AUTOSAR XML (schema 4-2-2)
package /System
  system System
package /EcuInstance
  18 x ecu instance:
    CVM9: associated-com-i-pdu-group=ipdugroupCVM9OUT
      can communication controller CVM9_CanCluster: can-controller-attributes=can-controller-configuration={sync-jump-width=0, time-seg-1=0, time-seg-2=0}
      can communication connector connectorCVM9_CanCluster: comm-controller=CVM9_CanCluster
    CVM10: associated-com-i-pdu-group=ipdugroupCVM10OUT
      can communication controller CVM10_CanCluster: can-controller-attributes=can-controller-configuration={sync-jump-width=0, time-seg-1=0, time-seg-2=0}
      can communication connector connectorCVM10_CanCluster: comm-controller=CVM10_CanCluster
    CVM8: associated-com-i-pdu-group=ipdugroupCVM8OUT
      can communication controller CVM8_CanCluster: can-controller-attributes=can-controller-configuration={sync-jump-width=0, time-seg-1=0, time-seg-2=0}
      can communication connector connectorCVM8_CanCluster: comm-controller=CVM8_CanCluster
    CVM11: associated-com-i-pdu-group=ipdugroupCVM11OUT
      can communication controller CVM11_CanCluster: can-controller-attributes=can-controller-configuration={sync-jump-width=0, time-seg-1=0, time-seg-2=0}
      can communication connector connectorCVM11_CanCluster: comm-controller=CVM11_CanCluster
    CVM7: associated-com-i-pdu-group=ipdugroupCVM7OUT
      can communication controller CVM7_CanCluster: can-controller-attributes=can-controller-configuration={sync-jump-width=0, time-seg-1=0, time-seg-2=0}
      can communication connector connectorCVM7_CanCluster: comm-controller=CVM7_CanCluster
    CVM12: associated-com-i-pdu-group=ipdugroupCVM12OUT
      can communication controller CVM12_CanCluster: can-controller-attributes=can-controller-configuration={sync-jump-width=0, time-seg-1=0, time-seg-2=0}
      can communication connector connectorCVM12_CanCluster: comm-controller=CVM12_CanCluster
    CVM6: associated-com-i-pdu-group=ipdugroupCVM6OUT
      can communication controller CVM6_CanCluster: can-controller-attributes=can-controller-configuration={sync-jump-width=0, time-seg-1=0, time-seg-2=0}
      can communication connector connectorCVM6_CanCluster: comm-controller=CVM6_CanCluster
    CVM5: associated-com-i-pdu-group=ipdugroupCVM5OUT
      can communication controller CVM5_CanCluster: can-controller-attributes=can-controller-configuration={sync-jump-width=0, time-seg-1=0, time-seg-2=0}
      can communication connector connectorCVM5_CanCluster: comm-controller=CVM5_CanCluster
    CVM4: associated-com-i-pdu-group=ipdugroupCVM4OUT
      can communication controller CVM4_CanCluster: can-controller-attributes=can-controller-configuration={sync-jump-width=0, time-seg-1=0, time-seg-2=0}
      can communication connector connectorCVM4_CanCluster: comm-controller=CVM4_CanCluster
    CVM3: associated-com-i-pdu-group=ipdugroupCVM3OUT
      can communication controller CVM3_CanCluster: can-controller-attributes=can-controller-configuration={sync-jump-width=0, time-seg-1=0, time-seg-2=0}
      can communication connector connectorCVM3_CanCluster: comm-controller=CVM3_CanCluster
    DCF: associated-com-i-pdu-group=[ipdugroupDCFOUT, ipdugroupDCFIN]
      can communication controller DCF_CanCluster: can-controller-attributes=can-controller-configuration={sync-jump-width=0, time-seg-1=0, time-seg-2=0}
      can communication connector connectorDCF_CanCluster: comm-controller=DCF_CanCluster
    CMP: associated-com-i-pdu-group=[ipdugroupCMPIN, ipdugroupCMPOUT]
      can communication controller CMP_CanCluster: can-controller-attributes=can-controller-configuration={sync-jump-width=0, time-seg-1=0, time-seg-2=0}
      can communication connector connectorCMP_CanCluster: comm-controller=CMP_CanCluster
    CVM2: associated-com-i-pdu-group=ipdugroupCVM2OUT
      can communication controller CVM2_CanCluster: can-controller-attributes=can-controller-configuration={sync-jump-width=0, time-seg-1=0, time-seg-2=0}
      can communication connector connectorCVM2_CanCluster: comm-controller=CVM2_CanCluster
    CVM1: associated-com-i-pdu-group=ipdugroupCVM1OUT
      can communication controller CVM1_CanCluster: can-controller-attributes=can-controller-configuration={sync-jump-width=0, time-seg-1=0, time-seg-2=0}
      can communication connector connectorCVM1_CanCluster: comm-controller=CVM1_CanCluster
    DCU: associated-com-i-pdu-group=[ipdugroupDCUIN, ipdugroupDCUOUT]
      can communication controller DCU_CanCluster: can-controller-attributes=can-controller-configuration={sync-jump-width=0, time-seg-1=0, time-seg-2=0}
      can communication connector connectorDCU_CanCluster: comm-controller=DCU_CanCluster
    HRB: associated-com-i-pdu-group=[ipdugroupHRBIN, ipdugroupHRBOUT]
      can communication controller HRB_CanCluster: can-controller-attributes=can-controller-configuration={sync-jump-width=0, time-seg-1=0, time-seg-2=0}
      can communication connector connectorHRB_CanCluster: comm-controller=HRB_CanCluster
    FCU: associated-com-i-pdu-group=[ipdugroupFCUIN, ipdugroupFCUOUT]
      can communication controller FCU_CanCluster: can-controller-attributes=can-controller-configuration={sync-jump-width=0, time-seg-1=0, time-seg-2=0}
      can communication connector connectorFCU_CanCluster: comm-controller=FCU_CanCluster
    HCU: associated-com-i-pdu-group=[ipdugroupHCUOUT, ipdugroupHCUIN]
      can communication controller HCU_CanCluster: can-controller-attributes=can-controller-configuration={sync-jump-width=0, time-seg-1=0, time-seg-2=0}
      can communication connector connectorHCU_CanCluster: comm-controller=HCU_CanCluster
package /VehicleTopology
  can cluster CanCluster: protocol-name=CAN, protocol-version=CAN, speed=1000
    can physical channel CanCluster
      comm-connectors:
        connectorCVM9_CanCluster
        connectorCVM10_CanCluster
        connectorCVM8_CanCluster
        connectorCVM11_CanCluster
        connectorCVM7_CanCluster
        connectorCVM12_CanCluster
        connectorCVM6_CanCluster
        connectorCVM5_CanCluster
        connectorCVM4_CanCluster
        connectorCVM3_CanCluster
        connectorDCF_CanCluster
        connectorCMP_CanCluster
        connectorCVM2_CanCluster
        connectorCVM1_CanCluster
        connectorDCU_CanCluster
        connectorHRB_CanCluster
        connectorFCU_CanCluster
        connectorHCU_CanCluster
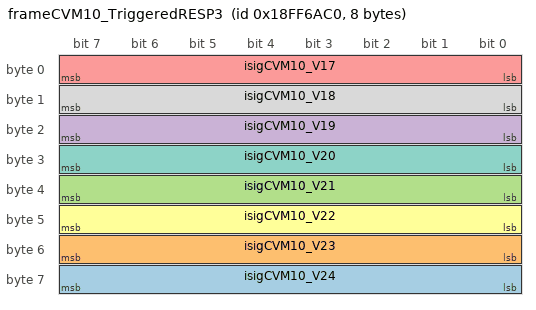
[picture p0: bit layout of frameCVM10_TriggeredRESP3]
      frame frameCVM10_TriggeredRESP3: id 0x18FF6AC0, from CVM10, to FCU, frame-length=8, can-addressing-mode=EXTENDED
        pdu ipduCVM10_TriggeredRESP3: length=8
          signal isigCVM10_V24: start 56, 8 bit, little-endian, system signal syssigCVM10_V24, init-value=0, base-type=uint8, compu-method=CVM10_V24, transfer-property=PENDING, to FCU
          signal isigCVM10_V23: start 48, 8 bit, little-endian, system signal syssigCVM10_V23, init-value=0, base-type=uint8, compu-method=CVM10_V23, transfer-property=PENDING, to FCU
          signal isigCVM10_V21: start 32, 8 bit, little-endian, system signal syssigCVM10_V21, init-value=0, base-type=uint8, compu-method=CVM10_V21, transfer-property=PENDING, to FCU
          signal isigCVM10_V19: start 16, 8 bit, little-endian, system signal syssigCVM10_V19, init-value=0, base-type=uint8, compu-method=CVM10_V19, transfer-property=PENDING, to FCU
          signal isigCVM10_V17: start 0, 8 bit, little-endian, system signal syssigCVM10_V17, init-value=0, base-type=uint8, compu-method=CVM10_V17, transfer-property=PENDING, to FCU
          signal isigCVM10_V22: start 40, 8 bit, little-endian, system signal syssigCVM10_V22, init-value=0, base-type=uint8, compu-method=CVM10_V22, transfer-property=PENDING, to FCU
          signal isigCVM10_V20: start 24, 8 bit, little-endian, system signal syssigCVM10_V20, init-value=0, base-type=uint8, compu-method=CVM10_V20, transfer-property=PENDING, to FCU
          signal isigCVM10_V18: start 8, 8 bit, little-endian, system signal syssigCVM10_V18, init-value=0, base-type=uint8, compu-method=CVM10_V18, transfer-property=PENDING, to FCU
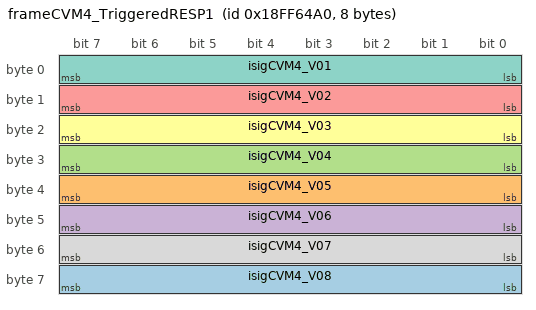
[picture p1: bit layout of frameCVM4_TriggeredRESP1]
      frame frameCVM4_TriggeredRESP1: id 0x18FF64A0, from CVM4, to FCU, frame-length=8, can-addressing-mode=EXTENDED
        pdu ipduCVM4_TriggeredRESP1: length=8
          signal isigCVM4_V08: start 56, 8 bit, little-endian, system signal syssigCVM4_V08, init-value=0, base-type=uint8, compu-method=CVM4_V08, transfer-property=PENDING, to FCU
          signal isigCVM4_V05: start 32, 8 bit, little-endian, system signal syssigCVM4_V05, init-value=0, base-type=uint8, compu-method=CVM4_V05, transfer-property=PENDING, to FCU
          signal isigCVM4_V04: start 24, 8 bit, little-endian, system signal syssigCVM4_V04, init-value=0, base-type=uint8, compu-method=CVM4_V04, transfer-property=PENDING, to FCU
          signal isigCVM4_V06: start 40, 8 bit, little-endian, system signal syssigCVM4_V06, init-value=0, base-type=uint8, compu-method=CVM4_V06, transfer-property=PENDING, to FCU
          signal isigCVM4_V02: start 8, 8 bit, little-endian, system signal syssigCVM4_V02, init-value=0, base-type=uint8, compu-method=CVM4_V02, transfer-property=PENDING, to FCU
          signal isigCVM4_V03: start 16, 8 bit, little-endian, system signal syssigCVM4_V03, init-value=0, base-type=uint8, compu-method=CVM4_V03, transfer-property=PENDING, to FCU
          signal isigCVM4_V01: start 0, 8 bit, little-endian, system signal syssigCVM4_V01, init-value=0, base-type=uint8, compu-method=CVM4_V01, transfer-property=PENDING, to FCU
          signal isigCVM4_V07: start 48, 8 bit, little-endian, system signal syssigCVM4_V07, init-value=0, base-type=uint8, compu-method=CVM4_V07, transfer-property=PENDING, to FCU
      frame frameCANC_HRB_CMD_Manual: id 0xCFFA63D, from FCU, to HRB, frame-length=8, can-addressing-mode=EXTENDED
        pdu ipduCANC_HRB_CMD_Manual: length=8, minimum-delay=0.0, transmission-mode-true-timing=cyclic-timing={time-offset=0.0, time-period=0.1}
          signal isigQ_HRBSet_Manual: start 0, 16 bit, little-endian, system signal syssigQ_HRBSet_Manual, init-value=0, base-type=uint16, compu-method=Q_HRBSet_Manual, transfer-property=PENDING, to HRB
          signal isigHRB_MFGEn_Manual: start 34, 2 bit, little-endian, system signal syssigHRB_MFGEn_Manual, init-value=0, base-type=uint8, compu-method=HRB_MFGEn_Manual, transfer-property=PENDING, to HRB
          signal isigHRB_PumpEn_Manual: start 32, 2 bit, little-endian, system signal syssigHRB_PumpEn_Manual, init-value=0, base-type=uint8, compu-method=HRB_PumpEn_Manual, transfer-property=PENDING, to HRB
          signal isigSpd_HRBSet_Manual: start 16, 16 bit, little-endian, system signal syssigSpd_HRBSet_Manual, init-value=0, base-type=uint16, compu-method=Spd_HRBSet_Manual, transfer-property=PENDING, to HRB
      frame frameCVM12_RESP: id 0x18FF6C10, from CVM12, to FCU, frame-length=8, can-addressing-mode=EXTENDED
        pdu ipduCVM12_RESP: length=8, minimum-delay=0.0, transmission-mode-true-timing=cyclic-timing={time-offset=0.0, time-period=0.1}
          signal isigCVM12_VMin: start 16, 8 bit, little-endian, system signal syssigCVM12_VMin, init-value=0, base-type=uint8, compu-method=CVM12_VMin, transfer-property=PENDING, to FCU
          signal isigCVM12_Var: start 48, 16 bit, little-endian, system signal syssigCVM12_Var, init-value=0, base-type=uint16, compu-method=CVM12_Var, transfer-property=PENDING, to FCU
          signal isigCVM12_Total: start 32, 16 bit, little-endian, system signal syssigCVM12_Total, init-value=0, base-type=uint16, compu-method=CVM12_Total, transfer-property=PENDING, to FCU
          signal isigCVM12_VMinCH: start 24, 8 bit, little-endian, system signal syssigCVM12_VMinCH, init-value=0, base-type=uint8, compu-method=CVM12_VMinCH, transfer-property=PENDING, to FCU
          signal isigCVM12_VMaxCH: start 8, 8 bit, little-endian, system signal syssigCVM12_VMaxCH, init-value=0, base-type=uint8, compu-method=CVM12_VMaxCH, transfer-property=PENDING, to FCU
          signal isigCVM12_VMax: start 0, 8 bit, little-endian, system signal syssigCVM12_VMax, init-value=0, base-type=uint8, compu-method=CVM12_VMax, transfer-property=PENDING, to FCU
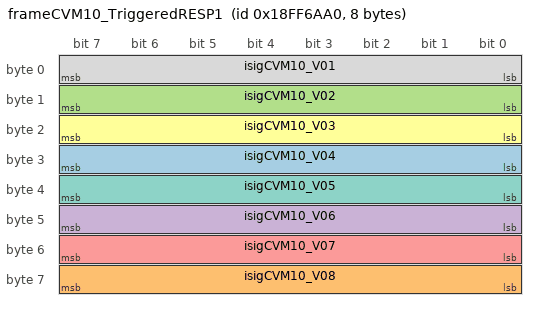
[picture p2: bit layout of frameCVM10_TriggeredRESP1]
      frame frameCVM10_TriggeredRESP1: id 0x18FF6AA0, from CVM10, to FCU, frame-length=8, can-addressing-mode=EXTENDED
        pdu ipduCVM10_TriggeredRESP1: length=8
          signal isigCVM10_V04: start 24, 8 bit, little-endian, system signal syssigCVM10_V04, init-value=0, base-type=uint8, compu-method=CVM10_V04, transfer-property=PENDING, to FCU
          signal isigCVM10_V08: start 56, 8 bit, little-endian, system signal syssigCVM10_V08, init-value=0, base-type=uint8, compu-method=CVM10_V08, transfer-property=PENDING, to FCU
          signal isigCVM10_V02: start 8, 8 bit, little-endian, system signal syssigCVM10_V02, init-value=0, base-type=uint8, compu-method=CVM10_V02, transfer-property=PENDING, to FCU
          signal isigCVM10_V06: start 40, 8 bit, little-endian, system signal syssigCVM10_V06, init-value=0, base-type=uint8, compu-method=CVM10_V06, transfer-property=PENDING, to FCU
          signal isigCVM10_V07: start 48, 8 bit, little-endian, system signal syssigCVM10_V07, init-value=0, base-type=uint8, compu-method=CVM10_V07, transfer-property=PENDING, to FCU
          signal isigCVM10_V03: start 16, 8 bit, little-endian, system signal syssigCVM10_V03, init-value=0, base-type=uint8, compu-method=CVM10_V03, transfer-property=PENDING, to FCU
          signal isigCVM10_V05: start 32, 8 bit, little-endian, system signal syssigCVM10_V05, init-value=0, base-type=uint8, compu-method=CVM10_V05, transfer-property=PENDING, to FCU
          signal isigCVM10_V01: start 0, 8 bit, little-endian, system signal syssigCVM10_V01, init-value=0, base-type=uint8, compu-method=CVM10_V01, transfer-property=PENDING, to FCU
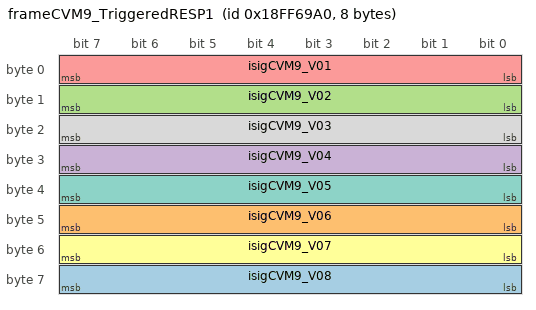
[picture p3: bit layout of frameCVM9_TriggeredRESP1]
      frame frameCVM9_TriggeredRESP1: id 0x18FF69A0, from CVM9, to FCU, frame-length=8, can-addressing-mode=EXTENDED
        pdu ipduCVM9_TriggeredRESP1: length=8
          signal isigCVM9_V08: start 56, 8 bit, little-endian, system signal syssigCVM9_V08, init-value=0, base-type=uint8, compu-method=CVM9_V08, transfer-property=PENDING, to FCU
          signal isigCVM9_V06: start 40, 8 bit, little-endian, system signal syssigCVM9_V06, init-value=0, base-type=uint8, compu-method=CVM9_V06, transfer-property=PENDING, to FCU
          signal isigCVM9_V02: start 8, 8 bit, little-endian, system signal syssigCVM9_V02, init-value=0, base-type=uint8, compu-method=CVM9_V02, transfer-property=PENDING, to FCU
          signal isigCVM9_V04: start 24, 8 bit, little-endian, system signal syssigCVM9_V04, init-value=0, base-type=uint8, compu-method=CVM9_V04, transfer-property=PENDING, to FCU
          signal isigCVM9_V01: start 0, 8 bit, little-endian, system signal syssigCVM9_V01, init-value=0, base-type=uint8, compu-method=CVM9_V01, transfer-property=PENDING, to FCU
          signal isigCVM9_V07: start 48, 8 bit, little-endian, system signal syssigCVM9_V07, init-value=0, base-type=uint8, compu-method=CVM9_V07, transfer-property=PENDING, to FCU
          signal isigCVM9_V05: start 32, 8 bit, little-endian, system signal syssigCVM9_V05, init-value=0, base-type=uint8, compu-method=CVM9_V05, transfer-property=PENDING, to FCU
          signal isigCVM9_V03: start 16, 8 bit, little-endian, system signal syssigCVM9_V03, init-value=0, base-type=uint8, compu-method=CVM9_V03, transfer-property=PENDING, to FCU
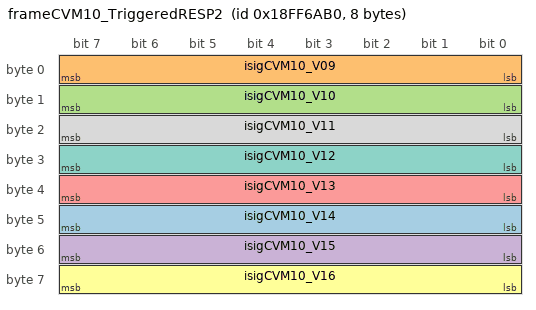
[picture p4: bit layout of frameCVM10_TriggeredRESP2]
      frame frameCVM10_TriggeredRESP2: id 0x18FF6AB0, from CVM10, to FCU, frame-length=8, can-addressing-mode=EXTENDED
        pdu ipduCVM10_TriggeredRESP2: length=8
          signal isigCVM10_V14: start 40, 8 bit, little-endian, system signal syssigCVM10_V14, init-value=0, base-type=uint8, compu-method=CVM10_V14, transfer-property=PENDING, to FCU
          signal isigCVM10_V09: start 0, 8 bit, little-endian, system signal syssigCVM10_V09, init-value=0, base-type=uint8, compu-method=CVM10_V09, transfer-property=PENDING, to FCU
          signal isigCVM10_V10: start 8, 8 bit, little-endian, system signal syssigCVM10_V10, init-value=0, base-type=uint8, compu-method=CVM10_V10, transfer-property=PENDING, to FCU
          signal isigCVM10_V15: start 48, 8 bit, little-endian, system signal syssigCVM10_V15, init-value=0, base-type=uint8, compu-method=CVM10_V15, transfer-property=PENDING, to FCU
          signal isigCVM10_V13: start 32, 8 bit, little-endian, system signal syssigCVM10_V13, init-value=0, base-type=uint8, compu-method=CVM10_V13, transfer-property=PENDING, to FCU
          signal isigCVM10_V16: start 56, 8 bit, little-endian, system signal syssigCVM10_V16, init-value=0, base-type=uint8, compu-method=CVM10_V16, transfer-property=PENDING, to FCU
          signal isigCVM10_V12: start 24, 8 bit, little-endian, system signal syssigCVM10_V12, init-value=0, base-type=uint8, compu-method=CVM10_V12, transfer-property=PENDING, to FCU
          signal isigCVM10_V11: start 16, 8 bit, little-endian, system signal syssigCVM10_V11, init-value=0, base-type=uint8, compu-method=CVM10_V11, transfer-property=PENDING, to FCU
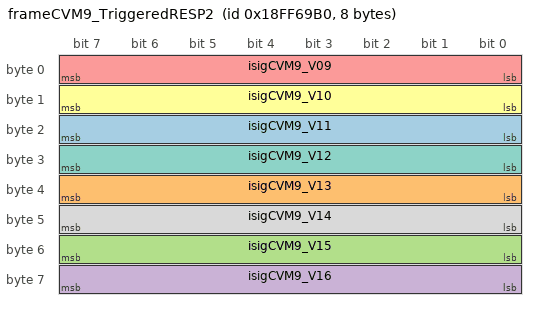
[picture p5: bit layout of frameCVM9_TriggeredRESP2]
      frame frameCVM9_TriggeredRESP2: id 0x18FF69B0, from CVM9, to FCU, frame-length=8, can-addressing-mode=EXTENDED
        pdu ipduCVM9_TriggeredRESP2: length=8
          signal isigCVM9_V11: start 16, 8 bit, little-endian, system signal syssigCVM9_V11, init-value=0, base-type=uint8, compu-method=CVM9_V11, transfer-property=PENDING, to FCU
          signal isigCVM9_V13: start 32, 8 bit, little-endian, system signal syssigCVM9_V13, init-value=0, base-type=uint8, compu-method=CVM9_V13, transfer-property=PENDING, to FCU
          signal isigCVM9_V15: start 48, 8 bit, little-endian, system signal syssigCVM9_V15, init-value=0, base-type=uint8, compu-method=CVM9_V15, transfer-property=PENDING, to FCU
          signal isigCVM9_V16: start 56, 8 bit, little-endian, system signal syssigCVM9_V16, init-value=0, base-type=uint8, compu-method=CVM9_V16, transfer-property=PENDING, to FCU
          signal isigCVM9_V09: start 0, 8 bit, little-endian, system signal syssigCVM9_V09, init-value=0, base-type=uint8, compu-method=CVM9_V09, transfer-property=PENDING, to FCU
          signal isigCVM9_V10: start 8, 8 bit, little-endian, system signal syssigCVM9_V10, init-value=0, base-type=uint8, compu-method=CVM9_V10, transfer-property=PENDING, to FCU
          signal isigCVM9_V12: start 24, 8 bit, little-endian, system signal syssigCVM9_V12, init-value=0, base-type=uint8, compu-method=CVM9_V12, transfer-property=PENDING, to FCU
          signal isigCVM9_V14: start 40, 8 bit, little-endian, system signal syssigCVM9_V14, init-value=0, base-type=uint8, compu-method=CVM9_V14, transfer-property=PENDING, to FCU
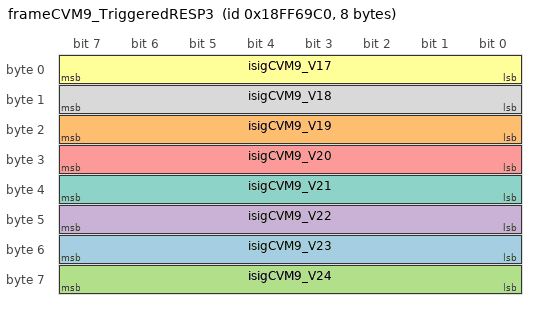
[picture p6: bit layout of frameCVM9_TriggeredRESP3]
      frame frameCVM9_TriggeredRESP3: id 0x18FF69C0, from CVM9, to FCU, frame-length=8, can-addressing-mode=EXTENDED
        pdu ipduCVM9_TriggeredRESP3: length=8
          signal isigCVM9_V23: start 48, 8 bit, little-endian, system signal syssigCVM9_V23, init-value=0, base-type=uint8, compu-method=CVM9_V23, transfer-property=PENDING, to FCU
          signal isigCVM9_V19: start 16, 8 bit, little-endian, system signal syssigCVM9_V19, init-value=0, base-type=uint8, compu-method=CVM9_V19, transfer-property=PENDING, to FCU
          signal isigCVM9_V24: start 56, 8 bit, little-endian, system signal syssigCVM9_V24, init-value=0, base-type=uint8, compu-method=CVM9_V24, transfer-property=PENDING, to FCU
          signal isigCVM9_V22: start 40, 8 bit, little-endian, system signal syssigCVM9_V22, init-value=0, base-type=uint8, compu-method=CVM9_V22, transfer-property=PENDING, to FCU
          signal isigCVM9_V20: start 24, 8 bit, little-endian, system signal syssigCVM9_V20, init-value=0, base-type=uint8, compu-method=CVM9_V20, transfer-property=PENDING, to FCU
          signal isigCVM9_V17: start 0, 8 bit, little-endian, system signal syssigCVM9_V17, init-value=0, base-type=uint8, compu-method=CVM9_V17, transfer-property=PENDING, to FCU
          signal isigCVM9_V21: start 32, 8 bit, little-endian, system signal syssigCVM9_V21, init-value=0, base-type=uint8, compu-method=CVM9_V21, transfer-property=PENDING, to FCU
          signal isigCVM9_V18: start 8, 8 bit, little-endian, system signal syssigCVM9_V18, init-value=0, base-type=uint8, compu-method=CVM9_V18, transfer-property=PENDING, to FCU
      frame frameCANC_CVM_TriggeredCMD_Manual: id 0xFF6002, from FCU, frame-length=8, can-addressing-mode=EXTENDED
        pdu ipduCANC_CVM_TriggeredCMD_Manual: length=8, minimum-delay=0.0, transmission-mode-true-timing=cyclic-timing={time-offset=0.0, time-period=0.1}
          signal isigCVM_Triggered_Manual: start 0, 1 bit, little-endian, system signal syssigCVM_Triggered_Manual, init-value=0, base-type=uint8, compu-method=CVM_Triggered_Manual, transfer-property=PENDING
      frame frameCVM8_RESP: id 0x18FF6810, from CVM8, to FCU, frame-length=8, can-addressing-mode=EXTENDED
        pdu ipduCVM8_RESP: length=8
          signal isigCVM8_Var: start 48, 16 bit, little-endian, system signal syssigCVM8_Var, init-value=0, base-type=uint16, compu-method=CVM8_Var, transfer-property=PENDING, to FCU
          signal isigCVM8_VMaxCH: start 8, 8 bit, little-endian, system signal syssigCVM8_VMaxCH, init-value=0, base-type=uint8, compu-method=CVM8_VMaxCH, transfer-property=PENDING, to FCU
          signal isigCVM8_VMinCH: start 24, 8 bit, little-endian, system signal syssigCVM8_VMinCH, init-value=0, base-type=uint8, compu-method=CVM8_VMinCH, transfer-property=PENDING, to FCU
          signal isigCVM8_VMin: start 16, 8 bit, little-endian, system signal syssigCVM8_VMin, init-value=0, base-type=uint8, compu-method=CVM8_VMin, transfer-property=PENDING, to FCU
          signal isigCVM8_VMax: start 0, 8 bit, little-endian, system signal syssigCVM8_VMax, init-value=0, base-type=uint8, compu-method=CVM8_VMax, transfer-property=PENDING, to FCU
          signal isigCVM8_Total: start 32, 16 bit, little-endian, system signal syssigCVM8_Total, init-value=0, base-type=uint16, compu-method=CVM8_Total, transfer-property=PENDING, to FCU
      frame frameCVM1_RESP: id 0x18FF6110, from CVM1, to FCU, frame-length=8, can-addressing-mode=EXTENDED
        pdu ipduCVM1_RESP: length=8, minimum-delay=0.0, transmission-mode-true-timing=cyclic-timing={time-offset=0.0, time-period=0.1}
          signal isigCVM1_VMax: start 0, 8 bit, little-endian, system signal syssigCVM1_VMax, init-value=0, base-type=uint8, compu-method=CVM1_VMax, transfer-property=PENDING, to FCU
          signal isigCVM1_VMin: start 16, 8 bit, little-endian, system signal syssigCVM1_VMin, init-value=0, base-type=uint8, compu-method=CVM1_VMin, transfer-property=PENDING, to FCU
          signal isigCVM1_VMaxCH: start 8, 8 bit, little-endian, system signal syssigCVM1_VMaxCH, init-value=0, base-type=uint8, compu-method=CVM1_VMaxCH, transfer-property=PENDING, to FCU
          signal isigCVM1_VMinCH: start 24, 8 bit, little-endian, system signal syssigCVM1_VMinCH, init-value=0, base-type=uint8, compu-method=CVM1_VMinCH, transfer-property=PENDING, to FCU
          signal isigCVM1_Total: start 32, 16 bit, little-endian, system signal syssigCVM1_Total, init-value=0, base-type=uint16, compu-method=CVM1_Total, transfer-property=PENDING, to FCU
          signal isigCVM1_Var: start 48, 16 bit, little-endian, system signal syssigCVM1_Var, init-value=0, base-type=uint16, compu-method=CVM1_Var, transfer-property=PENDING, to FCU
      frame frameCVM11_RESP: id 0x18FF6B10, from CVM11, to FCU, frame-length=8, can-addressing-mode=EXTENDED
        pdu ipduCVM11_RESP: length=8, minimum-delay=0.0, transmission-mode-true-timing=cyclic-timing={time-offset=0.0, time-period=0.1}
          signal isigCVM11_Var: start 48, 16 bit, little-endian, system signal syssigCVM11_Var, init-value=0, base-type=uint16, compu-method=CVM11_Var, transfer-property=PENDING, to FCU
          signal isigCVM11_VMin: start 16, 8 bit, little-endian, system signal syssigCVM11_VMin, init-value=0, base-type=uint8, compu-method=CVM11_VMin, transfer-property=PENDING, to FCU
          signal isigCVM11_Total: start 32, 16 bit, little-endian, system signal syssigCVM11_Total, init-value=0, base-type=uint16, compu-method=CVM11_Total, transfer-property=PENDING, to FCU
          signal isigCVM11_VMinCH: start 24, 8 bit, little-endian, system signal syssigCVM11_VMinCH, init-value=0, base-type=uint8, compu-method=CVM11_VMinCH, transfer-property=PENDING, to FCU
          signal isigCVM11_VMax: start 0, 8 bit, little-endian, system signal syssigCVM11_VMax, init-value=0, base-type=uint8, compu-method=CVM11_VMax, transfer-property=PENDING, to FCU
          signal isigCVM11_VMaxCH: start 8, 8 bit, little-endian, system signal syssigCVM11_VMaxCH, init-value=0, base-type=uint8, compu-method=CVM11_VMaxCH, transfer-property=PENDING, to FCU
      frame frameCANC_DCU_CMD1_Manual: id 0xFF1101, from FCU, to DCU, frame-length=8, can-addressing-mode=EXTENDED
        pdu ipduCANC_DCU_CMD1_Manual: length=8, minimum-delay=0.0, transmission-mode-true-timing=cyclic-timing={time-offset=0.0, time-period=0.1}
          signal isigFC_OutputPower_Manual: start 48, 8 bit, little-endian, system signal syssigFC_OutputPower_Manual, init-value=0, base-type=uint8, compu-method=FC_OutputPower_Manual, transfer-property=PENDING
          signal isigDCU_Mode_Manual: start 56, 8 bit, little-endian, system signal syssigDCU_Mode_Manual, init-value=0, base-type=uint8, compu-method=DCU_Mode_Manual, transfer-property=PENDING, to DCU
          signal isigT_FCSet_Manual: start 0, 8 bit, little-endian, system signal syssigT_FCSet_Manual, init-value=0, base-type=uint8, compu-method=T_FCSet_Manual, transfer-property=PENDING, to DCU
          signal isigTDiff_FCSet_Manual: start 16, 8 bit, little-endian, system signal syssigTDiff_FCSet_Manual, init-value=0, base-type=uint8, compu-method=TDiff_FCSet_Manual, transfer-property=PENDING, to DCU
          signal isigT_AMB_Manual: start 40, 8 bit, little-endian, system signal syssigT_AMB_Manual, init-value=0, base-type=uint8, compu-method=T_AMB_Manual, transfer-property=PENDING
      frame frameDCF_RESP1: id 0x18FF3110, from DCF, to FCU, frame-length=8, can-addressing-mode=EXTENDED
        pdu ipduDCF_RESP1: length=8, minimum-delay=0.0, transmission-mode-true-timing=cyclic-timing={time-offset=0.0, time-period=0.1}
          signal isigIIn_DCF: start 48, 16 bit, little-endian, system signal syssigIIn_DCF, init-value=0, base-type=uint16, compu-method=IIn_DCF, transfer-property=PENDING, to FCU
          signal isigIOut_DCF: start 16, 16 bit, little-endian, system signal syssigIOut_DCF, init-value=0, base-type=uint16, compu-method=IOut_DCF, transfer-property=PENDING, to FCU
          signal isigVOut_DCF: start 0, 16 bit, little-endian, system signal syssigVOut_DCF, init-value=0, base-type=uint16, compu-method=VOut_DCF, transfer-property=PENDING, to FCU
          signal isigVIn1_DCF: start 32, 16 bit, little-endian, system signal syssigVIn1_DCF, init-value=0, base-type=uint16, compu-method=VIn1_DCF, transfer-property=PENDING, to FCU
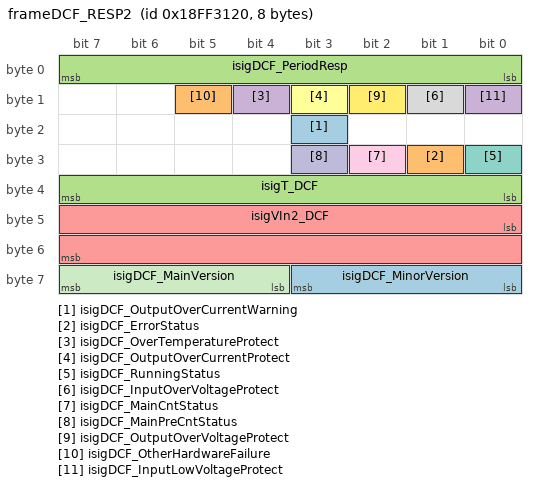
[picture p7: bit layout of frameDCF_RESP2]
      frame frameDCF_RESP2: id 0x18FF3120, from DCF, to FCU, frame-length=8, can-addressing-mode=EXTENDED
        pdu ipduDCF_RESP2: length=8
          signal isigDCF_OutputOverCurrentWarning: start 19, 1 bit, little-endian, system signal syssigDCF_OutputOverCurrentWarning, init-value=0, base-type=uint8, compu-method=DCF_OutputOverCurrentWarning, transfer-property=PENDING, to FCU
          signal isigDCF_ErrorStatus: start 25, 1 bit, little-endian, system signal syssigDCF_ErrorStatus, init-value=0, base-type=uint8, compu-method=DCF_ErrorStatus, transfer-property=PENDING
          signal isigT_DCF: start 32, 8 bit, little-endian, system signal syssigT_DCF, init-value=0, base-type=uint8, compu-method=T_DCF, transfer-property=PENDING, to FCU
          signal isigDCF_OverTemperatureProtect: start 12, 1 bit, little-endian, system signal syssigDCF_OverTemperatureProtect, init-value=0, base-type=uint8, compu-method=DCF_OverTemperatureProtect, transfer-property=PENDING, to FCU
          signal isigVIn2_DCF: start 40, 16 bit, little-endian, system signal syssigVIn2_DCF, init-value=0, base-type=uint16, compu-method=VIn2_DCF, transfer-property=PENDING, to FCU
          signal isigDCF_OutputOverCurrentProtect: start 11, 1 bit, little-endian, system signal syssigDCF_OutputOverCurrentProtect, init-value=0, base-type=uint8, compu-method=DCF_OutputOverCurrentProtect, transfer-property=PENDING, to FCU
          signal isigDCF_RunningStatus: start 24, 1 bit, little-endian, system signal syssigDCF_RunningStatus, init-value=0, base-type=uint8, compu-method=DCF_RunningStatus, transfer-property=PENDING
          signal isigDCF_InputOverVoltageProtect: start 9, 1 bit, little-endian, system signal syssigDCF_InputOverVoltageProtect, init-value=0, base-type=uint8, compu-method=DCF_InputOverVoltageProtect, transfer-property=PENDING, to FCU
          signal isigDCF_MainCntStatus: start 26, 1 bit, little-endian, system signal syssigDCF_MainCntStatus, init-value=0, base-type=uint8, compu-method=DCF_MainCntStatus, transfer-property=PENDING, to FCU
          signal isigDCF_MainPreCntStatus: start 27, 1 bit, little-endian, system signal syssigDCF_MainPreCntStatus, init-value=0, base-type=uint8, compu-method=DCF_MainPreCntStatus, transfer-property=PENDING, to FCU
          signal isigDCF_MainVersion: start 60, 4 bit, little-endian, system signal syssigDCF_MainVersion, init-value=0, base-type=uint8, compu-method=DCF_MainVersion, transfer-property=PENDING, to FCU
          signal isigDCF_OutputOverVoltageProtect: start 10, 1 bit, little-endian, system signal syssigDCF_OutputOverVoltageProtect, init-value=0, base-type=uint8, compu-method=DCF_OutputOverVoltageProtect, transfer-property=PENDING, to FCU
          signal isigDCF_MinorVersion: start 56, 4 bit, little-endian, system signal syssigDCF_MinorVersion, init-value=0, base-type=uint8, compu-method=DCF_MinorVersion, transfer-property=PENDING, to FCU
          signal isigDCF_OtherHardwareFailure: start 13, 1 bit, little-endian, system signal syssigDCF_OtherHardwareFailure, init-value=0, base-type=uint8, compu-method=DCF_OtherHardwareFailure, transfer-property=PENDING, to FCU
          signal isigDCF_PeriodResp: start 0, 8 bit, little-endian, system signal syssigDCF_PeriodResp, init-value=0, base-type=uint8, compu-method=DCF_PeriodResp, transfer-property=PENDING, to FCU
          signal isigDCF_InputLowVoltageProtect: start 8, 1 bit, little-endian, system signal syssigDCF_InputLowVoltageProtect, init-value=0, base-type=uint8, compu-method=DCF_InputLowVoltageProtect, transfer-property=PENDING, to FCU
      frame frameCANC_DCU_CMD2_Manual: id 0xFF1102, from FCU, to DCU, frame-length=8, can-addressing-mode=EXTENDED
        pdu ipduCANC_DCU_CMD2_Manual: length=8, minimum-delay=0.0, transmission-mode-true-timing=cyclic-timing={time-offset=0.0, time-period=0.1}
          signal isigWP_Set_Manual: start 32, 8 bit, little-endian, system signal syssigWP_Set_Manual, init-value=0, base-type=uint8, compu-method=WP_Set_Manual, transfer-property=PENDING, to DCU
          signal isigFAN3_Set_Manual: start 16, 8 bit, little-endian, system signal syssigFAN3_Set_Manual, init-value=0, base-type=uint8, compu-method=FAN3_Set_Manual, transfer-property=PENDING, to DCU
          signal isigFAN1_Set_Manual: start 0, 8 bit, little-endian, system signal syssigFAN1_Set_Manual, init-value=0, base-type=uint8, compu-method=FAN1_Set_Manual, transfer-property=PENDING, to DCU
          signal isigTV_DI_Manual: start 56, 1 bit, little-endian, system signal syssigTV_DI_Manual, init-value=0, base-type=uint8, compu-method=TV_DI_Manual, transfer-property=PENDING, to DCU
          signal isigFAN2_Set_Manual: start 8, 8 bit, little-endian, system signal syssigFAN2_Set_Manual, init-value=0, base-type=uint8, compu-method=FAN2_Set_Manual, transfer-property=PENDING, to DCU
          signal isigFAN4_Set_Manual: start 24, 8 bit, little-endian, system signal syssigFAN4_Set_Manual, init-value=0, base-type=uint8, compu-method=FAN4_Set_Manual, transfer-property=PENDING
      frame frameCVM7_RESP: id 0x18FF6710, from CVM7, to FCU, frame-length=8, can-addressing-mode=EXTENDED
        pdu ipduCVM7_RESP: length=8
          signal isigCVM7_VMax: start 0, 8 bit, little-endian, system signal syssigCVM7_VMax, init-value=0, base-type=uint8, compu-method=CVM7_VMax, transfer-property=PENDING, to FCU
          signal isigCVM7_Total: start 32, 16 bit, little-endian, system signal syssigCVM7_Total, init-value=0, base-type=uint16, compu-method=CVM7_Total, transfer-property=PENDING, to FCU
          signal isigCVM7_VMinCH: start 24, 8 bit, little-endian, system signal syssigCVM7_VMinCH, init-value=0, base-type=uint8, compu-method=CVM7_VMinCH, transfer-property=PENDING, to FCU
          signal isigCVM7_VMin: start 16, 8 bit, little-endian, system signal syssigCVM7_VMin, init-value=0, base-type=uint8, compu-method=CVM7_VMin, transfer-property=PENDING, to FCU
          signal isigCVM7_Var: start 48, 16 bit, little-endian, system signal syssigCVM7_Var, init-value=0, base-type=uint16, compu-method=CVM7_Var, transfer-property=PENDING, to FCU
          signal isigCVM7_VMaxCH: start 8, 8 bit, little-endian, system signal syssigCVM7_VMaxCH, init-value=0, base-type=uint8, compu-method=CVM7_VMaxCH, transfer-property=PENDING, to FCU
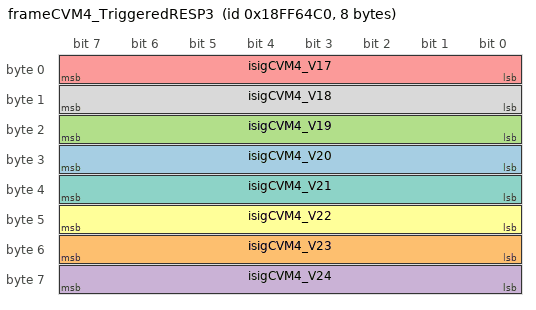
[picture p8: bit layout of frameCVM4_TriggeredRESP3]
      frame frameCVM4_TriggeredRESP3: id 0x18FF64C0, from CVM4, to FCU, frame-length=8, can-addressing-mode=EXTENDED
        pdu ipduCVM4_TriggeredRESP3: length=8
          signal isigCVM4_V20: start 24, 8 bit, little-endian, system signal syssigCVM4_V20, init-value=0, base-type=uint8, compu-method=CVM4_V20, transfer-property=PENDING, to FCU
          signal isigCVM4_V23: start 48, 8 bit, little-endian, system signal syssigCVM4_V23, init-value=0, base-type=uint8, compu-method=CVM4_V23, transfer-property=PENDING, to FCU
          signal isigCVM4_V19: start 16, 8 bit, little-endian, system signal syssigCVM4_V19, init-value=0, base-type=uint8, compu-method=CVM4_V19, transfer-property=PENDING, to FCU
          signal isigCVM4_V24: start 56, 8 bit, little-endian, system signal syssigCVM4_V24, init-value=0, base-type=uint8, compu-method=CVM4_V24, transfer-property=PENDING, to FCU
          signal isigCVM4_V17: start 0, 8 bit, little-endian, system signal syssigCVM4_V17, init-value=0, base-type=uint8, compu-method=CVM4_V17, transfer-property=PENDING, to FCU
          signal isigCVM4_V22: start 40, 8 bit, little-endian, system signal syssigCVM4_V22, init-value=0, base-type=uint8, compu-method=CVM4_V22, transfer-property=PENDING, to FCU
          signal isigCVM4_V21: start 32, 8 bit, little-endian, system signal syssigCVM4_V21, init-value=0, base-type=uint8, compu-method=CVM4_V21, transfer-property=PENDING, to FCU
          signal isigCVM4_V18: start 8, 8 bit, little-endian, system signal syssigCVM4_V18, init-value=0, base-type=uint8, compu-method=CVM4_V18, transfer-property=PENDING, to FCU
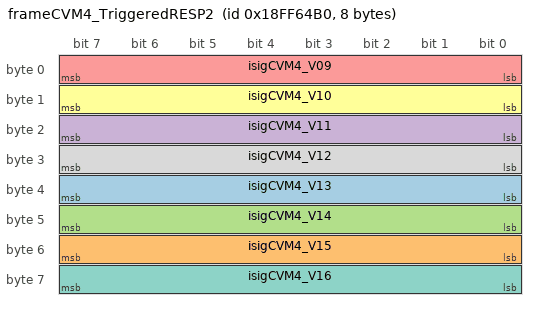
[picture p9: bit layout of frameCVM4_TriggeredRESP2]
      frame frameCVM4_TriggeredRESP2: id 0x18FF64B0, from CVM4, to FCU, frame-length=8, can-addressing-mode=EXTENDED
        pdu ipduCVM4_TriggeredRESP2: length=8
          signal isigCVM4_V13: start 32, 8 bit, little-endian, system signal syssigCVM4_V13, init-value=0, base-type=uint8, compu-method=CVM4_V13, transfer-property=PENDING, to FCU
          signal isigCVM4_V15: start 48, 8 bit, little-endian, system signal syssigCVM4_V15, init-value=0, base-type=uint8, compu-method=CVM4_V15, transfer-property=PENDING, to FCU
          signal isigCVM4_V14: start 40, 8 bit, little-endian, system signal syssigCVM4_V14, init-value=0, base-type=uint8, compu-method=CVM4_V14, transfer-property=PENDING, to FCU
          signal isigCVM4_V11: start 16, 8 bit, little-endian, system signal syssigCVM4_V11, init-value=0, base-type=uint8, compu-method=CVM4_V11, transfer-property=PENDING, to FCU
          signal isigCVM4_V09: start 0, 8 bit, little-endian, system signal syssigCVM4_V09, init-value=0, base-type=uint8, compu-method=CVM4_V09, transfer-property=PENDING, to FCU
          signal isigCVM4_V10: start 8, 8 bit, little-endian, system signal syssigCVM4_V10, init-value=0, base-type=uint8, compu-method=CVM4_V10, transfer-property=PENDING, to FCU
          signal isigCVM4_V16: start 56, 8 bit, little-endian, system signal syssigCVM4_V16, init-value=0, base-type=uint8, compu-method=CVM4_V16, transfer-property=PENDING, to FCU
          signal isigCVM4_V12: start 24, 8 bit, little-endian, system signal syssigCVM4_V12, init-value=0, base-type=uint8, compu-method=CVM4_V12, transfer-property=PENDING, to FCU
      frame frameCVM3_RESP: id 0x18FF6310, from CVM3, to FCU, frame-length=8, can-addressing-mode=EXTENDED
        pdu ipduCVM3_RESP: length=8
          signal isigCVM3_VMin: start 16, 8 bit, little-endian, system signal syssigCVM3_VMin, init-value=0, base-type=uint8, compu-method=CVM3_VMin, transfer-property=PENDING, to FCU
          signal isigCVM3_VMinCH: start 24, 8 bit, little-endian, system signal syssigCVM3_VMinCH, init-value=0, base-type=uint8, compu-method=CVM3_VMinCH, transfer-property=PENDING, to FCU
          signal isigCVM3_VMaxCH: start 8, 8 bit, little-endian, system signal syssigCVM3_VMaxCH, init-value=0, base-type=uint8, compu-method=CVM3_VMaxCH, transfer-property=PENDING, to FCU
          signal isigCVM3_Total: start 32, 16 bit, little-endian, system signal syssigCVM3_Total, init-value=0, base-type=uint16, compu-method=CVM3_Total, transfer-property=PENDING, to FCU
          signal isigCVM3_Var: start 48, 16 bit, little-endian, system signal syssigCVM3_Var, init-value=0, base-type=uint16, compu-method=CVM3_Var, transfer-property=PENDING, to FCU
          signal isigCVM3_VMax: start 0, 8 bit, little-endian, system signal syssigCVM3_VMax, init-value=0, base-type=uint8, compu-method=CVM3_VMax, transfer-property=PENDING, to FCU
      frame frameCVM9_RESP: id 0x18FF6910, from CVM9, to FCU, frame-length=8, can-addressing-mode=EXTENDED
        pdu ipduCVM9_RESP: length=8
          signal isigCVM9_VMaxCH: start 8, 8 bit, little-endian, system signal syssigCVM9_VMaxCH, init-value=0, base-type=uint8, compu-method=CVM9_VMaxCH, transfer-property=PENDING, to FCU
          signal isigCVM9_Var: start 48, 16 bit, little-endian, system signal syssigCVM9_Var, init-value=0, base-type=uint16, compu-method=CVM9_Var, transfer-property=PENDING, to FCU
          signal isigCVM9_VMin: start 16, 8 bit, little-endian, system signal syssigCVM9_VMin, init-value=0, base-type=uint8, compu-method=CVM9_VMin, transfer-property=PENDING, to FCU
          signal isigCVM9_Total: start 32, 16 bit, little-endian, system signal syssigCVM9_Total, init-value=0, base-type=uint16, compu-method=CVM9_Total, transfer-property=PENDING, to FCU
          signal isigCVM9_VMax: start 0, 8 bit, little-endian, system signal syssigCVM9_VMax, init-value=0, base-type=uint8, compu-method=CVM9_VMax, transfer-property=PENDING, to FCU
          signal isigCVM9_VMinCH: start 24, 8 bit, little-endian, system signal syssigCVM9_VMinCH, init-value=0, base-type=uint8, compu-method=CVM9_VMinCH, transfer-property=PENDING, to FCU
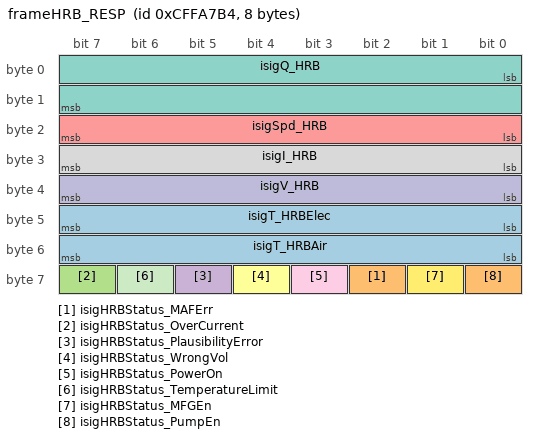
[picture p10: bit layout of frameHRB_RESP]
      frame frameHRB_RESP: id 0xCFFA7B4, from HRB, to FCU, frame-length=8, can-addressing-mode=EXTENDED
        pdu ipduHRB_RESP: length=8, minimum-delay=0.0, transmission-mode-true-timing=cyclic-timing={time-offset=0.0, time-period=0.1}
          signal isigT_HRBAir: start 48, 8 bit, little-endian, system signal syssigT_HRBAir, init-value=0, base-type=uint8, compu-method=T_HRBAir, transfer-property=PENDING, to FCU
          signal isigHRBStatus_MAFErr: start 58, 1 bit, little-endian, system signal syssigHRBStatus_MAFErr, init-value=0, base-type=uint8, compu-method=HRBStatus_MAFErr, transfer-property=PENDING, to FCU
          signal isigHRBStatus_OverCurrent: start 63, 1 bit, little-endian, system signal syssigHRBStatus_OverCurrent, init-value=0, base-type=uint8, compu-method=HRBStatus_OverCurrent, transfer-property=PENDING, to FCU
          signal isigHRBStatus_PlausibilityError: start 61, 1 bit, little-endian, system signal syssigHRBStatus_PlausibilityError, init-value=0, base-type=uint8, compu-method=HRBStatus_PlausibilityError, transfer-property=PENDING, to FCU
          signal isigSpd_HRB: start 16, 8 bit, little-endian, system signal syssigSpd_HRB, init-value=0, base-type=uint8, compu-method=Spd_HRB, transfer-property=PENDING, to FCU
          signal isigHRBStatus_WrongVol: start 60, 1 bit, little-endian, system signal syssigHRBStatus_WrongVol, init-value=0, base-type=uint8, compu-method=HRBStatus_WrongVol, transfer-property=PENDING, to FCU
          signal isigQ_HRB: start 0, 16 bit, little-endian, system signal syssigQ_HRB, init-value=0, base-type=uint16, compu-method=Q_HRB, transfer-property=PENDING, to FCU
          signal isigI_HRB: start 24, 8 bit, little-endian, system signal syssigI_HRB, init-value=0, base-type=uint8, compu-method=I_HRB, transfer-property=PENDING, to FCU
          signal isigHRBStatus_PowerOn: start 59, 1 bit, little-endian, system signal syssigHRBStatus_PowerOn, init-value=0, base-type=uint8, compu-method=HRBStatus_PowerOn, transfer-property=PENDING, to FCU
          signal isigV_HRB: start 32, 8 bit, little-endian, system signal syssigV_HRB, init-value=0, base-type=uint8, compu-method=V_HRB, transfer-property=PENDING, to FCU
          signal isigHRBStatus_TemperatureLimit: start 62, 1 bit, little-endian, system signal syssigHRBStatus_TemperatureLimit, init-value=0, base-type=uint8, compu-method=HRBStatus_TemperatureLimit, transfer-property=PENDING, to FCU
          signal isigHRBStatus_MFGEn: start 57, 1 bit, little-endian, system signal syssigHRBStatus_MFGEn, init-value=0, base-type=uint8, compu-method=HRBStatus_MFGEn, transfer-property=PENDING, to FCU
          signal isigT_HRBElec: start 40, 8 bit, little-endian, system signal syssigT_HRBElec, init-value=0, base-type=uint8, compu-method=T_HRBElec, transfer-property=PENDING, to FCU
          signal isigHRBStatus_PumpEn: start 56, 1 bit, little-endian, system signal syssigHRBStatus_PumpEn, init-value=0, base-type=uint8, compu-method=HRBStatus_PumpEn, transfer-property=PENDING, to FCU
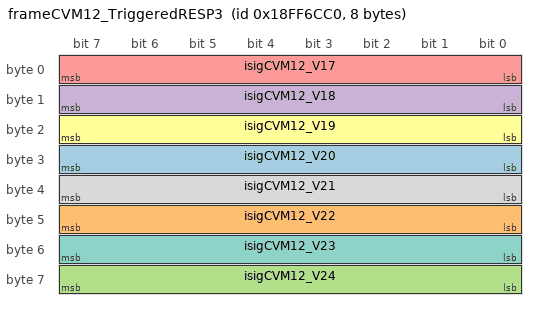
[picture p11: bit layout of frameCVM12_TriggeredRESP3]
      frame frameCVM12_TriggeredRESP3: id 0x18FF6CC0, from CVM12, to FCU, frame-length=8, can-addressing-mode=EXTENDED
        pdu ipduCVM12_TriggeredRESP3: length=8
          signal isigCVM12_V20: start 24, 8 bit, little-endian, system signal syssigCVM12_V20, init-value=0, base-type=uint8, compu-method=CVM12_V20, transfer-property=PENDING, to FCU
          signal isigCVM12_V22: start 40, 8 bit, little-endian, system signal syssigCVM12_V22, init-value=0, base-type=uint8, compu-method=CVM12_V22, transfer-property=PENDING, to FCU
          signal isigCVM12_V24: start 56, 8 bit, little-endian, system signal syssigCVM12_V24, init-value=0, base-type=uint8, compu-method=CVM12_V24, transfer-property=PENDING, to FCU
          signal isigCVM12_V18: start 8, 8 bit, little-endian, system signal syssigCVM12_V18, init-value=0, base-type=uint8, compu-method=CVM12_V18, transfer-property=PENDING, to FCU
          signal isigCVM12_V17: start 0, 8 bit, little-endian, system signal syssigCVM12_V17, init-value=0, base-type=uint8, compu-method=CVM12_V17, transfer-property=PENDING, to FCU
          signal isigCVM12_V19: start 16, 8 bit, little-endian, system signal syssigCVM12_V19, init-value=0, base-type=uint8, compu-method=CVM12_V19, transfer-property=PENDING, to FCU
          signal isigCVM12_V23: start 48, 8 bit, little-endian, system signal syssigCVM12_V23, init-value=0, base-type=uint8, compu-method=CVM12_V23, transfer-property=PENDING, to FCU
          signal isigCVM12_V21: start 32, 8 bit, little-endian, system signal syssigCVM12_V21, init-value=0, base-type=uint8, compu-method=CVM12_V21, transfer-property=PENDING, to FCU
      frame frameCVM6_RESP: id 0x18FF6610, from CVM6, to FCU, frame-length=8, can-addressing-mode=EXTENDED
        pdu ipduCVM6_RESP: length=8
          signal isigCVM6_VMax: start 0, 8 bit, little-endian, system signal syssigCVM6_VMax, init-value=0, base-type=uint8, compu-method=CVM6_VMax, transfer-property=PENDING, to FCU
          signal isigCVM6_VMin: start 16, 8 bit, little-endian, system signal syssigCVM6_VMin, init-value=0, base-type=uint8, compu-method=CVM6_VMin, transfer-property=PENDING, to FCU
          signal isigCVM6_VMinCH: start 24, 8 bit, little-endian, system signal syssigCVM6_VMinCH, init-value=0, base-type=uint8, compu-method=CVM6_VMinCH, transfer-property=PENDING, to FCU
          signal isigCVM6_Var: start 48, 16 bit, little-endian, system signal syssigCVM6_Var, init-value=0, base-type=uint16, compu-method=CVM6_Var, transfer-property=PENDING, to FCU
          signal isigCVM6_Total: start 32, 16 bit, little-endian, system signal syssigCVM6_Total, init-value=0, base-type=uint16, compu-method=CVM6_Total, transfer-property=PENDING, to FCU
          signal isigCVM6_VMaxCH: start 8, 8 bit, little-endian, system signal syssigCVM6_VMaxCH, init-value=0, base-type=uint8, compu-method=CVM6_VMaxCH, transfer-property=PENDING, to FCU
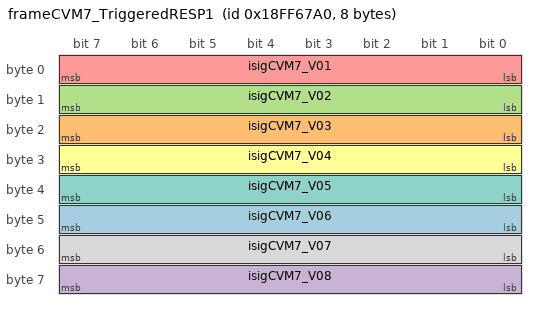
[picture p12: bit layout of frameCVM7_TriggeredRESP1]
      frame frameCVM7_TriggeredRESP1: id 0x18FF67A0, from CVM7, to FCU, frame-length=8, can-addressing-mode=EXTENDED
        pdu ipduCVM7_TriggeredRESP1: length=8
          signal isigCVM7_V06: start 40, 8 bit, little-endian, system signal syssigCVM7_V06, init-value=0, base-type=uint8, compu-method=CVM7_V06, transfer-property=PENDING, to FCU
          signal isigCVM7_V03: start 16, 8 bit, little-endian, system signal syssigCVM7_V03, init-value=0, base-type=uint8, compu-method=CVM7_V03, transfer-property=PENDING, to FCU
          signal isigCVM7_V02: start 8, 8 bit, little-endian, system signal syssigCVM7_V02, init-value=0, base-type=uint8, compu-method=CVM7_V02, transfer-property=PENDING, to FCU
          signal isigCVM7_V08: start 56, 8 bit, little-endian, system signal syssigCVM7_V08, init-value=0, base-type=uint8, compu-method=CVM7_V08, transfer-property=PENDING, to FCU
          signal isigCVM7_V01: start 0, 8 bit, little-endian, system signal syssigCVM7_V01, init-value=0, base-type=uint8, compu-method=CVM7_V01, transfer-property=PENDING, to FCU
          signal isigCVM7_V04: start 24, 8 bit, little-endian, system signal syssigCVM7_V04, init-value=0, base-type=uint8, compu-method=CVM7_V04, transfer-property=PENDING, to FCU
          signal isigCVM7_V05: start 32, 8 bit, little-endian, system signal syssigCVM7_V05, init-value=0, base-type=uint8, compu-method=CVM7_V05, transfer-property=PENDING, to FCU
          signal isigCVM7_V07: start 48, 8 bit, little-endian, system signal syssigCVM7_V07, init-value=0, base-type=uint8, compu-method=CVM7_V07, transfer-property=PENDING, to FCU
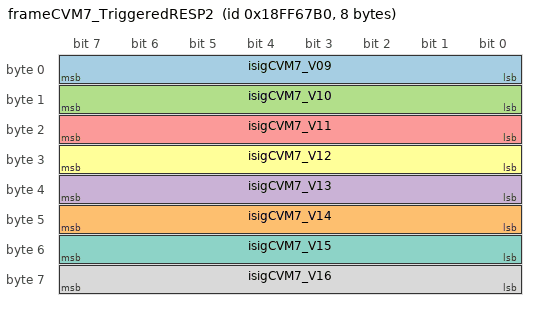
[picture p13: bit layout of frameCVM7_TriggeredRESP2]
      frame frameCVM7_TriggeredRESP2: id 0x18FF67B0, from CVM7, to FCU, frame-length=8, can-addressing-mode=EXTENDED
        pdu ipduCVM7_TriggeredRESP2: length=8
          signal isigCVM7_V09: start 0, 8 bit, little-endian, system signal syssigCVM7_V09, init-value=0, base-type=uint8, compu-method=CVM7_V09, transfer-property=PENDING, to FCU
          signal isigCVM7_V14: start 40, 8 bit, little-endian, system signal syssigCVM7_V14, init-value=0, base-type=uint8, compu-method=CVM7_V14, transfer-property=PENDING, to FCU
          signal isigCVM7_V10: start 8, 8 bit, little-endian, system signal syssigCVM7_V10, init-value=0, base-type=uint8, compu-method=CVM7_V10, transfer-property=PENDING, to FCU
          signal isigCVM7_V13: start 32, 8 bit, little-endian, system signal syssigCVM7_V13, init-value=0, base-type=uint8, compu-method=CVM7_V13, transfer-property=PENDING, to FCU
          signal isigCVM7_V11: start 16, 8 bit, little-endian, system signal syssigCVM7_V11, init-value=0, base-type=uint8, compu-method=CVM7_V11, transfer-property=PENDING, to FCU
          signal isigCVM7_V12: start 24, 8 bit, little-endian, system signal syssigCVM7_V12, init-value=0, base-type=uint8, compu-method=CVM7_V12, transfer-property=PENDING, to FCU
          signal isigCVM7_V15: start 48, 8 bit, little-endian, system signal syssigCVM7_V15, init-value=0, base-type=uint8, compu-method=CVM7_V15, transfer-property=PENDING, to FCU
          signal isigCVM7_V16: start 56, 8 bit, little-endian, system signal syssigCVM7_V16, init-value=0, base-type=uint8, compu-method=CVM7_V16, transfer-property=PENDING, to FCU
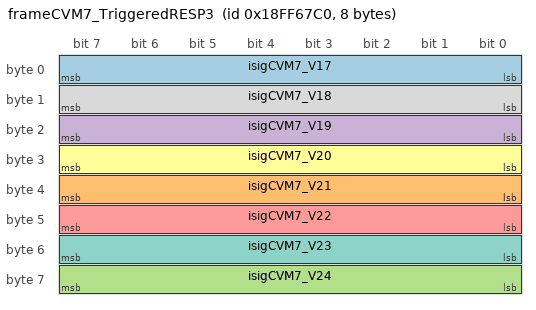
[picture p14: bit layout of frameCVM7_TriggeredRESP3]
      frame frameCVM7_TriggeredRESP3: id 0x18FF67C0, from CVM7, to FCU, frame-length=8, can-addressing-mode=EXTENDED
        pdu ipduCVM7_TriggeredRESP3: length=8
          signal isigCVM7_V17: start 0, 8 bit, little-endian, system signal syssigCVM7_V17, init-value=0, base-type=uint8, compu-method=CVM7_V17, transfer-property=PENDING, to FCU
          signal isigCVM7_V21: start 32, 8 bit, little-endian, system signal syssigCVM7_V21, init-value=0, base-type=uint8, compu-method=CVM7_V21, transfer-property=PENDING, to FCU
          signal isigCVM7_V24: start 56, 8 bit, little-endian, system signal syssigCVM7_V24, init-value=0, base-type=uint8, compu-method=CVM7_V24, transfer-property=PENDING, to FCU
          signal isigCVM7_V19: start 16, 8 bit, little-endian, system signal syssigCVM7_V19, init-value=0, base-type=uint8, compu-method=CVM7_V19, transfer-property=PENDING, to FCU
          signal isigCVM7_V22: start 40, 8 bit, little-endian, system signal syssigCVM7_V22, init-value=0, base-type=uint8, compu-method=CVM7_V22, transfer-property=PENDING, to FCU
          signal isigCVM7_V20: start 24, 8 bit, little-endian, system signal syssigCVM7_V20, init-value=0, base-type=uint8, compu-method=CVM7_V20, transfer-property=PENDING, to FCU
          signal isigCVM7_V23: start 48, 8 bit, little-endian, system signal syssigCVM7_V23, init-value=0, base-type=uint8, compu-method=CVM7_V23, transfer-property=PENDING, to FCU
          signal isigCVM7_V18: start 8, 8 bit, little-endian, system signal syssigCVM7_V18, init-value=0, base-type=uint8, compu-method=CVM7_V18, transfer-property=PENDING, to FCU
      frame frameCANC_CVM_CMD_Manual: id 0xFF6001, from FCU, frame-length=8, can-addressing-mode=EXTENDED
        pdu ipduCANC_CVM_CMD_Manual: length=8, minimum-delay=0.0, transmission-mode-true-timing=cyclic-timing={time-offset=0.0, time-period=0.1}
          signal isigCVM_Mode_Manual: start 56, 8 bit, little-endian, system signal syssigCVM_Mode_Manual, init-value=0, base-type=uint8, compu-method=CVM_Mode_Manual, transfer-property=PENDING
          signal isigCVM_ChSelect_Manual: start 48, 8 bit, little-endian, system signal syssigCVM_ChSelect_Manual, init-value=0, base-type=uint8, compu-method=CVM_ChSelect_Manual, transfer-property=PENDING
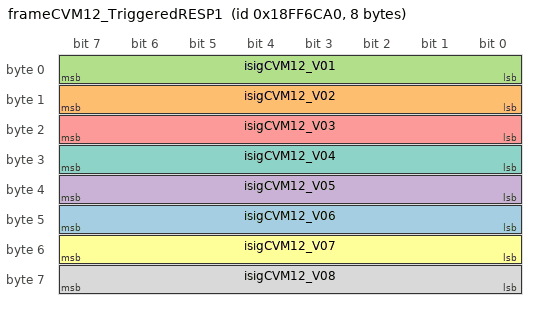
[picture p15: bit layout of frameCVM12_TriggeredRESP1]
      frame frameCVM12_TriggeredRESP1: id 0x18FF6CA0, from CVM12, to FCU, frame-length=8, can-addressing-mode=EXTENDED
        pdu ipduCVM12_TriggeredRESP1: length=8
          signal isigCVM12_V06: start 40, 8 bit, little-endian, system signal syssigCVM12_V06, init-value=0, base-type=uint8, compu-method=CVM12_V06, transfer-property=PENDING, to FCU
          signal isigCVM12_V02: start 8, 8 bit, little-endian, system signal syssigCVM12_V02, init-value=0, base-type=uint8, compu-method=CVM12_V02, transfer-property=PENDING, to FCU
          signal isigCVM12_V01: start 0, 8 bit, little-endian, system signal syssigCVM12_V01, init-value=0, base-type=uint8, compu-method=CVM12_V01, transfer-property=PENDING, to FCU
          signal isigCVM12_V05: start 32, 8 bit, little-endian, system signal syssigCVM12_V05, init-value=0, base-type=uint8, compu-method=CVM12_V05, transfer-property=PENDING, to FCU
          signal isigCVM12_V03: start 16, 8 bit, little-endian, system signal syssigCVM12_V03, init-value=0, base-type=uint8, compu-method=CVM12_V03, transfer-property=PENDING, to FCU
          signal isigCVM12_V07: start 48, 8 bit, little-endian, system signal syssigCVM12_V07, init-value=0, base-type=uint8, compu-method=CVM12_V07, transfer-property=PENDING, to FCU
          signal isigCVM12_V04: start 24, 8 bit, little-endian, system signal syssigCVM12_V04, init-value=0, base-type=uint8, compu-method=CVM12_V04, transfer-property=PENDING, to FCU
          signal isigCVM12_V08: start 56, 8 bit, little-endian, system signal syssigCVM12_V08, init-value=0, base-type=uint8, compu-method=CVM12_V08, transfer-property=PENDING, to FCU
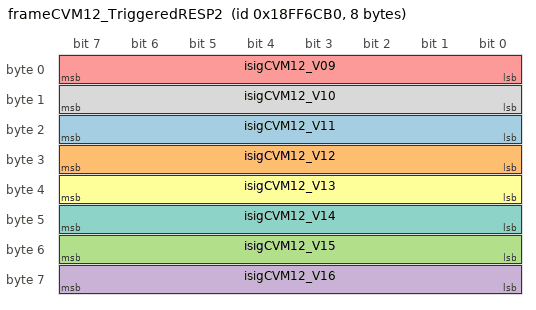
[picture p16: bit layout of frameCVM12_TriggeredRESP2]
      frame frameCVM12_TriggeredRESP2: id 0x18FF6CB0, from CVM12, to FCU, frame-length=8, can-addressing-mode=EXTENDED
        pdu ipduCVM12_TriggeredRESP2: length=8
          signal isigCVM12_V11: start 16, 8 bit, little-endian, system signal syssigCVM12_V11, init-value=0, base-type=uint8, compu-method=CVM12_V11, transfer-property=PENDING, to FCU
          signal isigCVM12_V12: start 24, 8 bit, little-endian, system signal syssigCVM12_V12, init-value=0, base-type=uint8, compu-method=CVM12_V12, transfer-property=PENDING, to FCU
          signal isigCVM12_V15: start 48, 8 bit, little-endian, system signal syssigCVM12_V15, init-value=0, base-type=uint8, compu-method=CVM12_V15, transfer-property=PENDING, to FCU
          signal isigCVM12_V16: start 56, 8 bit, little-endian, system signal syssigCVM12_V16, init-value=0, base-type=uint8, compu-method=CVM12_V16, transfer-property=PENDING, to FCU
          signal isigCVM12_V09: start 0, 8 bit, little-endian, system signal syssigCVM12_V09, init-value=0, base-type=uint8, compu-method=CVM12_V09, transfer-property=PENDING, to FCU
          signal isigCVM12_V13: start 32, 8 bit, little-endian, system signal syssigCVM12_V13, init-value=0, base-type=uint8, compu-method=CVM12_V13, transfer-property=PENDING, to FCU
          signal isigCVM12_V14: start 40, 8 bit, little-endian, system signal syssigCVM12_V14, init-value=0, base-type=uint8, compu-method=CVM12_V14, transfer-property=PENDING, to FCU
          signal isigCVM12_V10: start 8, 8 bit, little-endian, system signal syssigCVM12_V10, init-value=0, base-type=uint8, compu-method=CVM12_V10, transfer-property=PENDING, to FCU
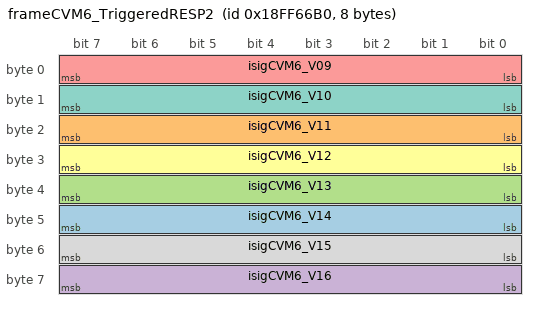
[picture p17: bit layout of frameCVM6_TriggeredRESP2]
      frame frameCVM6_TriggeredRESP2: id 0x18FF66B0, from CVM6, to FCU, frame-length=8, can-addressing-mode=EXTENDED
        pdu ipduCVM6_TriggeredRESP2: length=8
          signal isigCVM6_V14: start 40, 8 bit, little-endian, system signal syssigCVM6_V14, init-value=0, base-type=uint8, compu-method=CVM6_V14, transfer-property=PENDING, to FCU
          signal isigCVM6_V11: start 16, 8 bit, little-endian, system signal syssigCVM6_V11, init-value=0, base-type=uint8, compu-method=CVM6_V11, transfer-property=PENDING, to FCU
          signal isigCVM6_V13: start 32, 8 bit, little-endian, system signal syssigCVM6_V13, init-value=0, base-type=uint8, compu-method=CVM6_V13, transfer-property=PENDING, to FCU
          signal isigCVM6_V16: start 56, 8 bit, little-endian, system signal syssigCVM6_V16, init-value=0, base-type=uint8, compu-method=CVM6_V16, transfer-property=PENDING, to FCU
          signal isigCVM6_V09: start 0, 8 bit, little-endian, system signal syssigCVM6_V09, init-value=0, base-type=uint8, compu-method=CVM6_V09, transfer-property=PENDING, to FCU
          signal isigCVM6_V12: start 24, 8 bit, little-endian, system signal syssigCVM6_V12, init-value=0, base-type=uint8, compu-method=CVM6_V12, transfer-property=PENDING, to FCU
          signal isigCVM6_V10: start 8, 8 bit, little-endian, system signal syssigCVM6_V10, init-value=0, base-type=uint8, compu-method=CVM6_V10, transfer-property=PENDING, to FCU
          signal isigCVM6_V15: start 48, 8 bit, little-endian, system signal syssigCVM6_V15, init-value=0, base-type=uint8, compu-method=CVM6_V15, transfer-property=PENDING, to FCU
      frame frameCVM10_RESP: id 0x18FF6A10, from CVM10, to FCU, frame-length=8, can-addressing-mode=EXTENDED
        pdu ipduCVM10_RESP: length=8, minimum-delay=0.0, transmission-mode-true-timing=cyclic-timing={time-offset=0.0, time-period=0.1}
          signal isigCVM10_VMinCH: start 24, 8 bit, little-endian, system signal syssigCVM10_VMinCH, init-value=0, base-type=uint8, compu-method=CVM10_VMinCH, transfer-property=PENDING, to FCU
          signal isigCVM10_Total: start 32, 16 bit, little-endian, system signal syssigCVM10_Total, init-value=0, base-type=uint16, compu-method=CVM10_Total, transfer-property=PENDING, to FCU
          signal isigCVM10_VMaxCH: start 8, 8 bit, little-endian, system signal syssigCVM10_VMaxCH, init-value=0, base-type=uint8, compu-method=CVM10_VMaxCH, transfer-property=PENDING, to FCU
          signal isigCVM10_VMax: start 0, 8 bit, little-endian, system signal syssigCVM10_VMax, init-value=0, base-type=uint8, compu-method=CVM10_VMax, transfer-property=PENDING, to FCU
          signal isigCVM10_Var: start 48, 16 bit, little-endian, system signal syssigCVM10_Var, init-value=0, base-type=uint16, compu-method=CVM10_Var, transfer-property=PENDING, to FCU
          signal isigCVM10_VMin: start 16, 8 bit, little-endian, system signal syssigCVM10_VMin, init-value=0, base-type=uint8, compu-method=CVM10_VMin, transfer-property=PENDING, to FCU
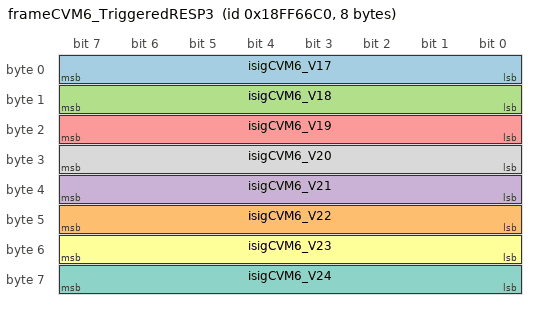
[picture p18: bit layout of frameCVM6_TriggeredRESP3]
      frame frameCVM6_TriggeredRESP3: id 0x18FF66C0, from CVM6, to FCU, frame-length=8, can-addressing-mode=EXTENDED
        pdu ipduCVM6_TriggeredRESP3: length=8
          signal isigCVM6_V17: start 0, 8 bit, little-endian, system signal syssigCVM6_V17, init-value=0, base-type=uint8, compu-method=CVM6_V17, transfer-property=PENDING, to FCU
          signal isigCVM6_V22: start 40, 8 bit, little-endian, system signal syssigCVM6_V22, init-value=0, base-type=uint8, compu-method=CVM6_V22, transfer-property=PENDING, to FCU
          signal isigCVM6_V18: start 8, 8 bit, little-endian, system signal syssigCVM6_V18, init-value=0, base-type=uint8, compu-method=CVM6_V18, transfer-property=PENDING, to FCU
          signal isigCVM6_V21: start 32, 8 bit, little-endian, system signal syssigCVM6_V21, init-value=0, base-type=uint8, compu-method=CVM6_V21, transfer-property=PENDING, to FCU
          signal isigCVM6_V19: start 16, 8 bit, little-endian, system signal syssigCVM6_V19, init-value=0, base-type=uint8, compu-method=CVM6_V19, transfer-property=PENDING, to FCU
          signal isigCVM6_V23: start 48, 8 bit, little-endian, system signal syssigCVM6_V23, init-value=0, base-type=uint8, compu-method=CVM6_V23, transfer-property=PENDING, to FCU
          signal isigCVM6_V24: start 56, 8 bit, little-endian, system signal syssigCVM6_V24, init-value=0, base-type=uint8, compu-method=CVM6_V24, transfer-property=PENDING, to FCU
          signal isigCVM6_V20: start 24, 8 bit, little-endian, system signal syssigCVM6_V20, init-value=0, base-type=uint8, compu-method=CVM6_V20, transfer-property=PENDING, to FCU
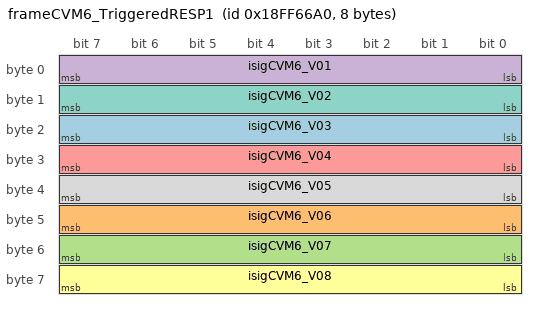
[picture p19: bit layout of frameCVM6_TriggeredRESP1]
      frame frameCVM6_TriggeredRESP1: id 0x18FF66A0, from CVM6, to FCU, frame-length=8, can-addressing-mode=EXTENDED
        pdu ipduCVM6_TriggeredRESP1: length=8
          signal isigCVM6_V03: start 16, 8 bit, little-endian, system signal syssigCVM6_V03, init-value=0, base-type=uint8, compu-method=CVM6_V03, transfer-property=PENDING, to FCU
          signal isigCVM6_V06: start 40, 8 bit, little-endian, system signal syssigCVM6_V06, init-value=0, base-type=uint8, compu-method=CVM6_V06, transfer-property=PENDING, to FCU
          signal isigCVM6_V07: start 48, 8 bit, little-endian, system signal syssigCVM6_V07, init-value=0, base-type=uint8, compu-method=CVM6_V07, transfer-property=PENDING, to FCU
          signal isigCVM6_V01: start 0, 8 bit, little-endian, system signal syssigCVM6_V01, init-value=0, base-type=uint8, compu-method=CVM6_V01, transfer-property=PENDING, to FCU
          signal isigCVM6_V04: start 24, 8 bit, little-endian, system signal syssigCVM6_V04, init-value=0, base-type=uint8, compu-method=CVM6_V04, transfer-property=PENDING, to FCU
          signal isigCVM6_V08: start 56, 8 bit, little-endian, system signal syssigCVM6_V08, init-value=0, base-type=uint8, compu-method=CVM6_V08, transfer-property=PENDING, to FCU
          signal isigCVM6_V02: start 8, 8 bit, little-endian, system signal syssigCVM6_V02, init-value=0, base-type=uint8, compu-method=CVM6_V02, transfer-property=PENDING, to FCU
          signal isigCVM6_V05: start 32, 8 bit, little-endian, system signal syssigCVM6_V05, init-value=0, base-type=uint8, compu-method=CVM6_V05, transfer-property=PENDING, to FCU
      frame frameCANC_CMP_CMD_Manual: id 0xFF7101, from FCU, to CMP, frame-length=8, can-addressing-mode=EXTENDED
        pdu ipduCANC_CMP_CMD_Manual: length=8, minimum-delay=0.0, transmission-mode-true-timing=cyclic-timing={time-offset=0.0, time-period=0.1}
          signal isigSpd_CMPSet_Manual: start 0, 16 bit, little-endian, system signal syssigSpd_CMPSet_Manual, init-value=0, base-type=uint16, compu-method=Spd_CMPSet_Manual, transfer-property=PENDING, to CMP
          signal isigCMP_En_Manual: start 16, 8 bit, little-endian, system signal syssigCMP_En_Manual, init-value=0, base-type=uint8, compu-method=CMP_En_Manual, transfer-property=PENDING, to CMP
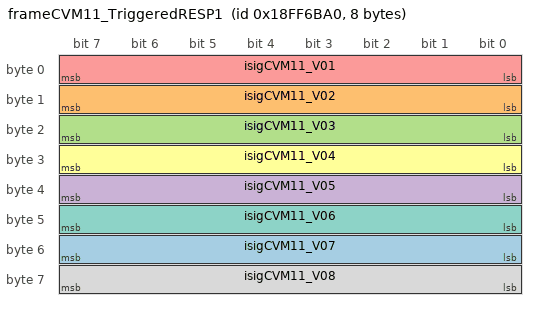
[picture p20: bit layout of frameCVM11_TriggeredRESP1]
      frame frameCVM11_TriggeredRESP1: id 0x18FF6BA0, from CVM11, to FCU, frame-length=8, can-addressing-mode=EXTENDED
        pdu ipduCVM11_TriggeredRESP1: length=8
          signal isigCVM11_V07: start 48, 8 bit, little-endian, system signal syssigCVM11_V07, init-value=0, base-type=uint8, compu-method=CVM11_V07, transfer-property=PENDING, to FCU
          signal isigCVM11_V02: start 8, 8 bit, little-endian, system signal syssigCVM11_V02, init-value=0, base-type=uint8, compu-method=CVM11_V02, transfer-property=PENDING, to FCU
          signal isigCVM11_V03: start 16, 8 bit, little-endian, system signal syssigCVM11_V03, init-value=0, base-type=uint8, compu-method=CVM11_V03, transfer-property=PENDING, to FCU
          signal isigCVM11_V05: start 32, 8 bit, little-endian, system signal syssigCVM11_V05, init-value=0, base-type=uint8, compu-method=CVM11_V05, transfer-property=PENDING, to FCU
          signal isigCVM11_V01: start 0, 8 bit, little-endian, system signal syssigCVM11_V01, init-value=0, base-type=uint8, compu-method=CVM11_V01, transfer-property=PENDING, to FCU
          signal isigCVM11_V04: start 24, 8 bit, little-endian, system signal syssigCVM11_V04, init-value=0, base-type=uint8, compu-method=CVM11_V04, transfer-property=PENDING, to FCU
          signal isigCVM11_V06: start 40, 8 bit, little-endian, system signal syssigCVM11_V06, init-value=0, base-type=uint8, compu-method=CVM11_V06, transfer-property=PENDING, to FCU
          signal isigCVM11_V08: start 56, 8 bit, little-endian, system signal syssigCVM11_V08, init-value=0, base-type=uint8, compu-method=CVM11_V08, transfer-property=PENDING, to FCU
      frame frameCVM5_RESP: id 0x18FF6510, from CVM5, to FCU, frame-length=8, can-addressing-mode=EXTENDED
        pdu ipduCVM5_RESP: length=8
          signal isigCVM5_Var: start 48, 16 bit, little-endian, system signal syssigCVM5_Var, init-value=0, base-type=uint16, compu-method=CVM5_Var, transfer-property=PENDING, to FCU
          signal isigCVM5_Total: start 32, 16 bit, little-endian, system signal syssigCVM5_Total, init-value=0, base-type=uint16, compu-method=CVM5_Total, transfer-property=PENDING, to FCU
          signal isigCVM5_VMax: start 0, 8 bit, little-endian, system signal syssigCVM5_VMax, init-value=0, base-type=uint8, compu-method=CVM5_VMax, transfer-property=PENDING, to FCU
          signal isigCVM5_VMaxCH: start 8, 8 bit, little-endian, system signal syssigCVM5_VMaxCH, init-value=0, base-type=uint8, compu-method=CVM5_VMaxCH, transfer-property=PENDING, to FCU
          signal isigCVM5_VMinCH: start 24, 8 bit, little-endian, system signal syssigCVM5_VMinCH, init-value=0, base-type=uint8, compu-method=CVM5_VMinCH, transfer-property=PENDING, to FCU
          signal isigCVM5_VMin: start 16, 8 bit, little-endian, system signal syssigCVM5_VMin, init-value=0, base-type=uint8, compu-method=CVM5_VMin, transfer-property=PENDING, to FCU
      frame frameCVM3_TriggeredRESP2: id 0x18FF63B0, from CVM3, to FCU, frame-length=8, can-addressing-mode=EXTENDED
        pdu ipduCVM3_TriggeredRESP2: length=8
          signal isigCVM3_V13: start 32, 8 bit, little-endian, system signal syssigCVM3_V13, init-value=0, base-type=uint8, compu-method=CVM3_V13, transfer-property=PENDING, to FCU
          signal isigCVM3_V10: start 8, 8 bit, little-endian, system signal syssigCVM3_V10, init-value=0, base-type=uint8, compu-method=CVM3_V10, transfer-property=PENDING, to FCU
          signal isigCVM3_V12: start 24, 8 bit, little-endian, system signal syssigCVM3_V12, init-value=0, base-type=uint8, compu-method=CVM3_V12, transfer-property=PENDING, to FCU
          signal isigCVM3_V14: start 40, 8 bit, little-endian, system signal syssigCVM3_V14, init-value=0, base-type=uint8, compu-method=CVM3_V14, transfer-property=PENDING, to FCU
          signal isigCVM3_V16: start 56, 8 bit, little-endian, system signal syssigCVM3_V16, init-value=0, base-type=uint8, compu-method=CVM3_V16, transfer-property=PENDING, to FCU
          signal isigCVM3_V09: start 0, 8 bit, little-endian, system signal syssigCVM3_V09, init-value=0, base-type=uint8, compu-method=CVM3_V09, transfer-property=PENDING, to FCU
          signal isigCVM3_V15: start 48, 8 bit, little-endian, system signal syssigCVM3_V15, init-value=0, base-type=uint8, compu-method=CVM3_V15, transfer-property=PENDING, to FCU
          signal isigCVM3_V11: start 16, 8 bit, little-endian, system signal syssigCVM3_V11, init-value=0, base-type=uint8, compu-method=CVM3_V11, transfer-property=PENDING, to FCU
      frame frameCVM3_TriggeredRESP1: id 0x18FF63A0, from CVM3, to FCU, frame-length=8, can-addressing-mode=EXTENDED
        pdu ipduCVM3_TriggeredRESP1: length=8
          signal isigCVM3_V05: start 32, 8 bit, little-endian, system signal syssigCVM3_V05, init-value=0, base-type=uint8, compu-method=CVM3_V05, transfer-property=PENDING, to FCU
          signal isigCVM3_V07: start 48, 8 bit, little-endian, system signal syssigCVM3_V07, init-value=0, base-type=uint8, compu-method=CVM3_V07, transfer-property=PENDING, to FCU
          signal isigCVM3_V03: start 16, 8 bit, little-endian, system signal syssigCVM3_V03, init-value=0, base-type=uint8, compu-method=CVM3_V03, transfer-property=PENDING, to FCU
          signal isigCVM3_V01: start 0, 8 bit, little-endian, system signal syssigCVM3_V01, init-value=0, base-type=uint8, compu-method=CVM3_V01, transfer-property=PENDING, to FCU
          signal isigCVM3_V06: start 40, 8 bit, little-endian, system signal syssigCVM3_V06, init-value=0, base-type=uint8, compu-method=CVM3_V06, transfer-property=PENDING, to FCU
          signal isigCVM3_V08: start 56, 8 bit, little-endian, system signal syssigCVM3_V08, init-value=0, base-type=uint8, compu-method=CVM3_V08, transfer-property=PENDING, to FCU
          signal isigCVM3_V04: start 24, 8 bit, little-endian, system signal syssigCVM3_V04, init-value=0, base-type=uint8, compu-method=CVM3_V04, transfer-property=PENDING, to FCU
          signal isigCVM3_V02: start 8, 8 bit, little-endian, system signal syssigCVM3_V02, init-value=0, base-type=uint8, compu-method=CVM3_V02, transfer-property=PENDING, to FCU
      frame frameCVM5_TriggeredRESP1: id 0x18FF65A0, from CVM5, to FCU, frame-length=8, can-addressing-mode=EXTENDED
        pdu ipduCVM5_TriggeredRESP1: length=8
          signal isigCVM5_V01: start 0, 8 bit, little-endian, system signal syssigCVM5_V01, init-value=0, base-type=uint8, compu-method=CVM5_V01, transfer-property=PENDING, to FCU
          signal isigCVM5_V04: start 24, 8 bit, little-endian, system signal syssigCVM5_V04, init-value=0, base-type=uint8, compu-method=CVM5_V04, transfer-property=PENDING, to FCU
          signal isigCVM5_V07: start 48, 8 bit, little-endian, system signal syssigCVM5_V07, init-value=0, base-type=uint8, compu-method=CVM5_V07, transfer-property=PENDING, to FCU
          signal isigCVM5_V05: start 32, 8 bit, little-endian, system signal syssigCVM5_V05, init-value=0, base-type=uint8, compu-method=CVM5_V05, transfer-property=PENDING, to FCU
          signal isigCVM5_V06: start 40, 8 bit, little-endian, system signal syssigCVM5_V06, init-value=0, base-type=uint8, compu-method=CVM5_V06, transfer-property=PENDING, to FCU
          signal isigCVM5_V03: start 16, 8 bit, little-endian, system signal syssigCVM5_V03, init-value=0, base-type=uint8, compu-method=CVM5_V03, transfer-property=PENDING, to FCU
          signal isigCVM5_V02: start 8, 8 bit, little-endian, system signal syssigCVM5_V02, init-value=0, base-type=uint8, compu-method=CVM5_V02, transfer-property=PENDING, to FCU
          signal isigCVM5_V08: start 56, 8 bit, little-endian, system signal syssigCVM5_V08, init-value=0, base-type=uint8, compu-method=CVM5_V08, transfer-property=PENDING, to FCU
      frame frameCVM5_TriggeredRESP2: id 0x18FF65B0, from CVM5, to FCU, frame-length=8, can-addressing-mode=EXTENDED
        pdu ipduCVM5_TriggeredRESP2: length=8
          signal isigCVM5_V15: start 48, 8 bit, little-endian, system signal syssigCVM5_V15, init-value=0, base-type=uint8, compu-method=CVM5_V15, transfer-property=PENDING, to FCU
          signal isigCVM5_V12: start 24, 8 bit, little-endian, system signal syssigCVM5_V12, init-value=0, base-type=uint8, compu-method=CVM5_V12, transfer-property=PENDING, to FCU
          signal isigCVM5_V14: start 40, 8 bit, little-endian, system signal syssigCVM5_V14, init-value=0, base-type=uint8, compu-method=CVM5_V14, transfer-property=PENDING, to FCU
          signal isigCVM5_V09: start 0, 8 bit, little-endian, system signal syssigCVM5_V09, init-value=0, base-type=uint8, compu-method=CVM5_V09, transfer-property=PENDING, to FCU
          signal isigCVM5_V10: start 8, 8 bit, little-endian, system signal syssigCVM5_V10, init-value=0, base-type=uint8, compu-method=CVM5_V10, transfer-property=PENDING, to FCU
          signal isigCVM5_V16: start 56, 8 bit, little-endian, system signal syssigCVM5_V16, init-value=0, base-type=uint8, compu-method=CVM5_V16, transfer-property=PENDING, to FCU
          signal isigCVM5_V13: start 32, 8 bit, little-endian, system signal syssigCVM5_V13, init-value=0, base-type=uint8, compu-method=CVM5_V13, transfer-property=PENDING, to FCU
          signal isigCVM5_V11: start 16, 8 bit, little-endian, system signal syssigCVM5_V11, init-value=0, base-type=uint8, compu-method=CVM5_V11, transfer-property=PENDING, to FCU
      frame frameCVM3_TriggeredRESP3: id 0x18FF63C0, from CVM3, to FCU, frame-length=8, can-addressing-mode=EXTENDED
        pdu ipduCVM3_TriggeredRESP3: length=8
          signal isigCVM3_V24: start 56, 8 bit, little-endian, system signal syssigCVM3_V24, init-value=0, base-type=uint8, compu-method=CVM3_V24, transfer-property=PENDING, to FCU
          signal isigCVM3_V23: start 48, 8 bit, little-endian, system signal syssigCVM3_V23, init-value=0, base-type=uint8, compu-method=CVM3_V23, transfer-property=PENDING, to FCU
          signal isigCVM3_V21: start 32, 8 bit, little-endian, system signal syssigCVM3_V21, init-value=0, base-type=uint8, compu-method=CVM3_V21, transfer-property=PENDING, to FCU
          signal isigCVM3_V18: start 8, 8 bit, little-endian, system signal syssigCVM3_V18, init-value=0, base-type=uint8, compu-method=CVM3_V18, transfer-property=PENDING, to FCU
          signal isigCVM3_V17: start 0, 8 bit, little-endian, system signal syssigCVM3_V17, init-value=0, base-type=uint8, compu-method=CVM3_V17, transfer-property=PENDING, to FCU
          signal isigCVM3_V20: start 24, 8 bit, little-endian, system signal syssigCVM3_V20, init-value=0, base-type=uint8, compu-method=CVM3_V20, transfer-property=PENDING, to FCU
          signal isigCVM3_V19: start 16, 8 bit, little-endian, system signal syssigCVM3_V19, init-value=0, base-type=uint8, compu-method=CVM3_V19, transfer-property=PENDING, to FCU
          signal isigCVM3_V22: start 40, 8 bit, little-endian, system signal syssigCVM3_V22, init-value=0, base-type=uint8, compu-method=CVM3_V22, transfer-property=PENDING, to FCU
      frame frameCANC_DCF_CMD_Manual: id 0xFF3101, from FCU, to DCF FCU, frame-length=8, can-addressing-mode=EXTENDED
        pdu ipduCANC_DCF_CMD_Manual: length=8, minimum-delay=0.0, transmission-mode-true-timing=cyclic-timing={time-offset=0.0, time-period=0.1}
          signal isigDCF_Reset_Manual: start 1, 1 bit, little-endian, system signal syssigDCF_Reset_Manual, init-value=0, base-type=uint8, compu-method=DCF_Reset_Manual, transfer-property=PENDING, to FCU
          signal isigDCF_ISet_Manual: start 40, 16 bit, little-endian, system signal syssigDCF_ISet_Manual, init-value=0, base-type=uint16, compu-method=DCF_ISet_Manual, transfer-property=PENDING, to DCF FCU
          signal isigDCF_PeriodCmd_Manual: start 8, 8 bit, little-endian, system signal syssigDCF_PeriodCmd_Manual, init-value=0, base-type=uint8, compu-method=DCF_PeriodCmd_Manual, transfer-property=PENDING, to FCU
          signal isigCNT_DCF_Manual: start 0, 1 bit, little-endian, system signal syssigCNT_DCF_Manual, init-value=0, base-type=uint8, compu-method=CNT_DCF_Manual, transfer-property=PENDING, to DCF
          signal isigDCF_En_Manual: start 56, 8 bit, little-endian, system signal syssigDCF_En_Manual, init-value=0, base-type=uint8, compu-method=DCF_En_Manual, transfer-property=PENDING, to DCF FCU
      frame frameCVM5_TriggeredRESP3: id 0x18FF65C0, from CVM5, to FCU, frame-length=8, can-addressing-mode=EXTENDED
        pdu ipduCVM5_TriggeredRESP3: length=8
          signal isigCVM5_V18: start 8, 8 bit, little-endian, system signal syssigCVM5_V18, init-value=0, base-type=uint8, compu-method=CVM5_V18, transfer-property=PENDING, to FCU
          signal isigCVM5_V22: start 40, 8 bit, little-endian, system signal syssigCVM5_V22, init-value=0, base-type=uint8, compu-method=CVM5_V22, transfer-property=PENDING, to FCU
          signal isigCVM5_V23: start 48, 8 bit, little-endian, system signal syssigCVM5_V23, init-value=0, base-type=uint8, compu-method=CVM5_V23, transfer-property=PENDING, to FCU
          signal isigCVM5_V20: start 24, 8 bit, little-endian, system signal syssigCVM5_V20, init-value=0, base-type=uint8, compu-method=CVM5_V20, transfer-property=PENDING, to FCU
          signal isigCVM5_V24: start 56, 8 bit, little-endian, system signal syssigCVM5_V24, init-value=0, base-type=uint8, compu-method=CVM5_V24, transfer-property=PENDING, to FCU
          signal isigCVM5_V17: start 0, 8 bit, little-endian, system signal syssigCVM5_V17, init-value=0, base-type=uint8, compu-method=CVM5_V17, transfer-property=PENDING, to FCU
          signal isigCVM5_V21: start 32, 8 bit, little-endian, system signal syssigCVM5_V21, init-value=0, base-type=uint8, compu-method=CVM5_V21, transfer-property=PENDING, to FCU
          signal isigCVM5_V19: start 16, 8 bit, little-endian, system signal syssigCVM5_V19, init-value=0, base-type=uint8, compu-method=CVM5_V19, transfer-property=PENDING, to FCU
      frame frameCVM11_TriggeredRESP2: id 0x18FF6BB0, from CVM11, to FCU, frame-length=8, can-addressing-mode=EXTENDED
        pdu ipduCVM11_TriggeredRESP2: length=8
          signal isigCVM11_V11: start 16, 8 bit, little-endian, system signal syssigCVM11_V11, init-value=0, base-type=uint8, compu-method=CVM11_V11, transfer-property=PENDING, to FCU
          signal isigCVM11_V13: start 32, 8 bit, little-endian, system signal syssigCVM11_V13, init-value=0, base-type=uint8, compu-method=CVM11_V13, transfer-property=PENDING, to FCU
          signal isigCVM11_V15: start 48, 8 bit, little-endian, system signal syssigCVM11_V15, init-value=0, base-type=uint8, compu-method=CVM11_V15, transfer-property=PENDING, to FCU
          signal isigCVM11_V09: start 0, 8 bit, little-endian, system signal syssigCVM11_V09, init-value=0, base-type=uint8, compu-method=CVM11_V09, transfer-property=PENDING, to FCU
          signal isigCVM11_V16: start 56, 8 bit, little-endian, system signal syssigCVM11_V16, init-value=0, base-type=uint8, compu-method=CVM11_V16, transfer-property=PENDING, to FCU
          signal isigCVM11_V14: start 40, 8 bit, little-endian, system signal syssigCVM11_V14, init-value=0, base-type=uint8, compu-method=CVM11_V14, transfer-property=PENDING, to FCU
          signal isigCVM11_V10: start 8, 8 bit, little-endian, system signal syssigCVM11_V10, init-value=0, base-type=uint8, compu-method=CVM11_V10, transfer-property=PENDING, to FCU
          signal isigCVM11_V12: start 24, 8 bit, little-endian, system signal syssigCVM11_V12, init-value=0, base-type=uint8, compu-method=CVM11_V12, transfer-property=PENDING, to FCU
      frame frameCVM11_TriggeredRESP3: id 0x18FF6BC0, from CVM11, to FCU, frame-length=8, can-addressing-mode=EXTENDED
        pdu ipduCVM11_TriggeredRESP3: length=8
          signal isigCVM11_V17: start 0, 8 bit, little-endian, system signal syssigCVM11_V17, init-value=0, base-type=uint8, compu-method=CVM11_V17, transfer-property=PENDING, to FCU
          signal isigCVM11_V22: start 40, 8 bit, little-endian, system signal syssigCVM11_V22, init-value=0, base-type=uint8, compu-method=CVM11_V22, transfer-property=PENDING, to FCU
          signal isigCVM11_V23: start 48, 8 bit, little-endian, system signal syssigCVM11_V23, init-value=0, base-type=uint8, compu-method=CVM11_V23, transfer-property=PENDING, to FCU
          signal isigCVM11_V24: start 56, 8 bit, little-endian, system signal syssigCVM11_V24, init-value=0, base-type=uint8, compu-method=CVM11_V24, transfer-property=PENDING, to FCU
          signal isigCVM11_V21: start 32, 8 bit, little-endian, system signal syssigCVM11_V21, init-value=0, base-type=uint8, compu-method=CVM11_V21, transfer-property=PENDING, to FCU
          signal isigCVM11_V19: start 16, 8 bit, little-endian, system signal syssigCVM11_V19, init-value=0, base-type=uint8, compu-method=CVM11_V19, transfer-property=PENDING, to FCU
          signal isigCVM11_V20: start 24, 8 bit, little-endian, system signal syssigCVM11_V20, init-value=0, base-type=uint8, compu-method=CVM11_V20, transfer-property=PENDING, to FCU
          signal isigCVM11_V18: start 8, 8 bit, little-endian, system signal syssigCVM11_V18, init-value=0, base-type=uint8, compu-method=CVM11_V18, transfer-property=PENDING, to FCU
      frame frameDCU_RESP1: id 0x18FF1110, from DCU, to FCU, frame-length=8, can-addressing-mode=EXTENDED
        pdu ipduDCU_RESP1: length=8, minimum-delay=0.0, transmission-mode-true-timing=cyclic-timing={time-offset=0.0, time-period=0.1}
          signal isigT_DIOut: start 16, 16 bit, little-endian, system signal syssigT_DIOut, init-value=0, base-type=uint16, compu-method=T_DIOut, transfer-property=PENDING, to FCU
          signal isigT_CMPWout: start 32, 8 bit, little-endian, system signal syssigT_CMPWout, init-value=0, base-type=uint8, compu-method=T_CMPWout, transfer-property=PENDING, to FCU
          signal isigT_DIIn: start 0, 16 bit, little-endian, system signal syssigT_DIIn, init-value=0, base-type=uint16, compu-method=T_DIIn, transfer-property=PENDING, to FCU
          signal isigC_DI: start 56, 8 bit, little-endian, system signal syssigC_DI, init-value=0, base-type=uint8, compu-method=C_DI, transfer-property=PENDING, to FCU
          signal isigT_DCFWout: start 40, 8 bit, little-endian, system signal syssigT_DCFWout, init-value=0, base-type=uint8, compu-method=T_DCFWout, transfer-property=PENDING, to FCU
          signal isigT_HEXWout: start 48, 8 bit, little-endian, system signal syssigT_HEXWout, init-value=0, base-type=uint8, compu-method=T_HEXWout, transfer-property=PENDING, to FCU
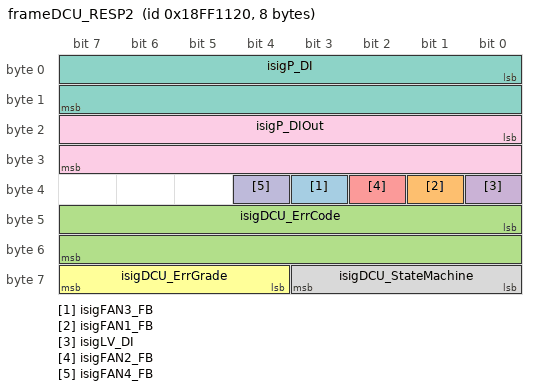
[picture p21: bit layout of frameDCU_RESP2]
      frame frameDCU_RESP2: id 0x18FF1120, from DCU, to FCU, frame-length=8, can-addressing-mode=EXTENDED
        pdu ipduDCU_RESP2: length=8
          signal isigFAN3_FB: start 35, 1 bit, little-endian, system signal syssigFAN3_FB, init-value=0, base-type=uint8, compu-method=FAN3_FB, transfer-property=PENDING, to FCU
          signal isigFAN1_FB: start 33, 1 bit, little-endian, system signal syssigFAN1_FB, init-value=0, base-type=uint8, compu-method=FAN1_FB, transfer-property=PENDING, to FCU
          signal isigDCU_ErrCode: start 40, 16 bit, little-endian, system signal syssigDCU_ErrCode, init-value=0, base-type=uint16, compu-method=DCU_ErrCode, transfer-property=PENDING, to FCU
          signal isigLV_DI: start 32, 1 bit, little-endian, system signal syssigLV_DI, init-value=0, base-type=uint8, compu-method=LV_DI, transfer-property=PENDING, to FCU
          signal isigFAN2_FB: start 34, 1 bit, little-endian, system signal syssigFAN2_FB, init-value=0, base-type=uint8, compu-method=FAN2_FB, transfer-property=PENDING, to FCU
          signal isigDCU_ErrGrade: start 60, 4 bit, little-endian, system signal syssigDCU_ErrGrade, init-value=0, base-type=uint8, compu-method=DCU_ErrGrade, transfer-property=PENDING, to FCU
          signal isigP_DI: start 0, 16 bit, little-endian, system signal syssigP_DI, init-value=0, base-type=uint16, compu-method=P_DI, transfer-property=PENDING, to FCU
          signal isigDCU_StateMachine: start 56, 4 bit, little-endian, system signal syssigDCU_StateMachine, init-value=0, base-type=uint8, compu-method=DCU_StateMachine, transfer-property=PENDING, to FCU
          signal isigP_DIOut: start 16, 16 bit, little-endian, system signal syssigP_DIOut, init-value=0, base-type=uint16, compu-method=P_DIOut, transfer-property=PENDING
          signal isigFAN4_FB: start 36, 1 bit, little-endian, system signal syssigFAN4_FB, init-value=0, base-type=uint8, compu-method=FAN4_FB, transfer-property=PENDING
      frame frameCVM8_TriggeredRESP2: id 0x18FF68B0, from CVM8, to FCU, frame-length=8, can-addressing-mode=EXTENDED
        pdu ipduCVM8_TriggeredRESP2: length=8
          signal isigCVM8_V13: start 32, 8 bit, little-endian, system signal syssigCVM8_V13, init-value=0, base-type=uint8, compu-method=CVM8_V13, transfer-property=PENDING, to FCU
          signal isigCVM8_V16: start 56, 8 bit, little-endian, system signal syssigCVM8_V16, init-value=0, base-type=uint8, compu-method=CVM8_V16, transfer-property=PENDING, to FCU
          signal isigCVM8_V12: start 24, 8 bit, little-endian, system signal syssigCVM8_V12, init-value=0, base-type=uint8, compu-method=CVM8_V12, transfer-property=PENDING, to FCU
          signal isigCVM8_V09: start 0, 8 bit, little-endian, system signal syssigCVM8_V09, init-value=0, base-type=uint8, compu-method=CVM8_V09, transfer-property=PENDING, to FCU
          signal isigCVM8_V10: start 8, 8 bit, little-endian, system signal syssigCVM8_V10, init-value=0, base-type=uint8, compu-method=CVM8_V10, transfer-property=PENDING, to FCU
          signal isigCVM8_V14: start 40, 8 bit, little-endian, system signal syssigCVM8_V14, init-value=0, base-type=uint8, compu-method=CVM8_V14, transfer-property=PENDING, to FCU
          signal isigCVM8_V11: start 16, 8 bit, little-endian, system signal syssigCVM8_V11, init-value=0, base-type=uint8, compu-method=CVM8_V11, transfer-property=PENDING, to FCU
          signal isigCVM8_V15: start 48, 8 bit, little-endian, system signal syssigCVM8_V15, init-value=0, base-type=uint8, compu-method=CVM8_V15, transfer-property=PENDING, to FCU
      frame frameCVM8_TriggeredRESP3: id 0x18FF68C0, from CVM8, to FCU, frame-length=8, can-addressing-mode=EXTENDED
        pdu ipduCVM8_TriggeredRESP3: length=8
          signal isigCVM8_V18: start 8, 8 bit, little-endian, system signal syssigCVM8_V18, init-value=0, base-type=uint8, compu-method=CVM8_V18, transfer-property=PENDING, to FCU
          signal isigCVM8_V21: start 32, 8 bit, little-endian, system signal syssigCVM8_V21, init-value=0, base-type=uint8, compu-method=CVM8_V21, transfer-property=PENDING, to FCU
          signal isigCVM8_V23: start 48, 8 bit, little-endian, system signal syssigCVM8_V23, init-value=0, base-type=uint8, compu-method=CVM8_V23, transfer-property=PENDING, to FCU
          signal isigCVM8_V22: start 40, 8 bit, little-endian, system signal syssigCVM8_V22, init-value=0, base-type=uint8, compu-method=CVM8_V22, transfer-property=PENDING, to FCU
          signal isigCVM8_V17: start 0, 8 bit, little-endian, system signal syssigCVM8_V17, init-value=0, base-type=uint8, compu-method=CVM8_V17, transfer-property=PENDING, to FCU
          signal isigCVM8_V24: start 56, 8 bit, little-endian, system signal syssigCVM8_V24, init-value=0, base-type=uint8, compu-method=CVM8_V24, transfer-property=PENDING, to FCU
          signal isigCVM8_V20: start 24, 8 bit, little-endian, system signal syssigCVM8_V20, init-value=0, base-type=uint8, compu-method=CVM8_V20, transfer-property=PENDING, to FCU
          signal isigCVM8_V19: start 16, 8 bit, little-endian, system signal syssigCVM8_V19, init-value=0, base-type=uint8, compu-method=CVM8_V19, transfer-property=PENDING, to FCU
      frame frameCVM8_TriggeredRESP1: id 0x18FF68A0, from CVM8, to FCU, frame-length=8, can-addressing-mode=EXTENDED
        pdu ipduCVM8_TriggeredRESP1: length=8
          signal isigCVM8_V02: start 8, 8 bit, little-endian, system signal syssigCVM8_V02, init-value=0, base-type=uint8, compu-method=CVM8_V02, transfer-property=PENDING, to FCU
          signal isigCVM8_V03: start 16, 8 bit, little-endian, system signal syssigCVM8_V03, init-value=0, base-type=uint8, compu-method=CVM8_V03, transfer-property=PENDING, to FCU
          signal isigCVM8_V05: start 32, 8 bit, little-endian, system signal syssigCVM8_V05, init-value=0, base-type=uint8, compu-method=CVM8_V05, transfer-property=PENDING, to FCU
          signal isigCVM8_V01: start 0, 8 bit, little-endian, system signal syssigCVM8_V01, init-value=0, base-type=uint8, compu-method=CVM8_V01, transfer-property=PENDING, to FCU
          signal isigCVM8_V07: start 48, 8 bit, little-endian, system signal syssigCVM8_V07, init-value=0, base-type=uint8, compu-method=CVM8_V07, transfer-property=PENDING, to FCU
          signal isigCVM8_V04: start 24, 8 bit, little-endian, system signal syssigCVM8_V04, init-value=0, base-type=uint8, compu-method=CVM8_V04, transfer-property=PENDING, to FCU
          signal isigCVM8_V06: start 40, 8 bit, little-endian, system signal syssigCVM8_V06, init-value=0, base-type=uint8, compu-method=CVM8_V06, transfer-property=PENDING, to FCU
          signal isigCVM8_V08: start 56, 8 bit, little-endian, system signal syssigCVM8_V08, init-value=0, base-type=uint8, compu-method=CVM8_V08, transfer-property=PENDING, to FCU
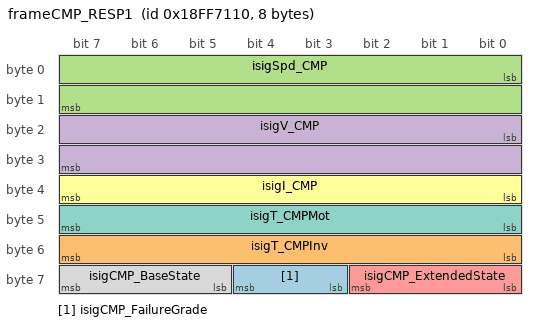
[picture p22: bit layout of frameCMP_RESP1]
      frame frameCMP_RESP1: id 0x18FF7110, from CMP, to FCU, frame-length=8, can-addressing-mode=EXTENDED
        pdu ipduCMP_RESP1: length=8, minimum-delay=0.0, transmission-mode-true-timing=cyclic-timing={time-offset=0.0, time-period=0.1}
          signal isigCMP_FailureGrade: start 59, 2 bit, little-endian, system signal syssigCMP_FailureGrade, init-value=0, base-type=uint8, compu-method=CMP_FailureGrade, transfer-property=PENDING, to FCU
          signal isigT_CMPInv: start 48, 8 bit, little-endian, system signal syssigT_CMPInv, init-value=0, base-type=uint8, compu-method=T_CMPInv, transfer-property=PENDING, to FCU
          signal isigSpd_CMP: start 0, 16 bit, little-endian, system signal syssigSpd_CMP, init-value=0, base-type=uint16, compu-method=Spd_CMP, transfer-property=PENDING, to FCU
          signal isigV_CMP: start 16, 16 bit, little-endian, system signal syssigV_CMP, init-value=0, base-type=uint16, compu-method=V_CMP, transfer-property=PENDING, to FCU
          signal isigCMP_ExtendedState: start 56, 3 bit, little-endian, system signal syssigCMP_ExtendedState, init-value=0, base-type=uint8, compu-method=CMP_ExtendedState, transfer-property=PENDING, to FCU
          signal isigI_CMP: start 32, 8 bit, little-endian, system signal syssigI_CMP, init-value=0, base-type=uint8, compu-method=I_CMP, transfer-property=PENDING, to FCU
          signal isigT_CMPMot: start 40, 8 bit, little-endian, system signal syssigT_CMPMot, init-value=0, base-type=uint8, compu-method=T_CMPMot, transfer-property=PENDING, to FCU
          signal isigCMP_BaseState: start 61, 3 bit, little-endian, system signal syssigCMP_BaseState, init-value=0, base-type=uint8, compu-method=CMP_BaseState, transfer-property=PENDING, to FCU
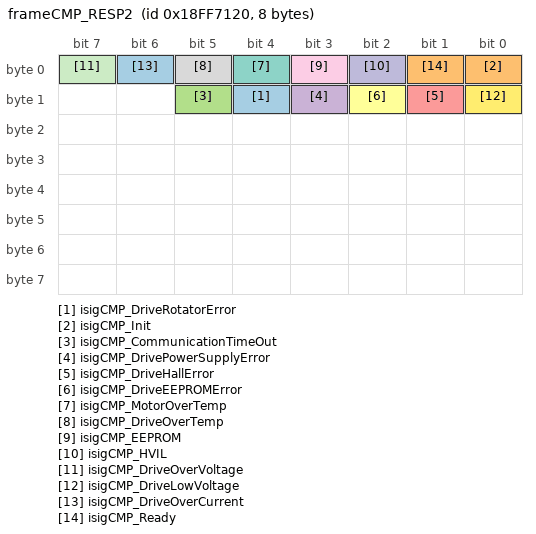
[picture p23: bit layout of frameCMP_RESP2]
      frame frameCMP_RESP2: id 0x18FF7120, from CMP, frame-length=8, can-addressing-mode=EXTENDED
        pdu ipduCMP_RESP2: length=8
          signal isigCMP_DriveRotatorError: start 12, 1 bit, little-endian, system signal syssigCMP_DriveRotatorError, init-value=0, base-type=uint8, compu-method=CMP_DriveRotatorError, transfer-property=PENDING
          signal isigCMP_Init: start 0, 1 bit, little-endian, system signal syssigCMP_Init, init-value=0, base-type=uint8, compu-method=CMP_Init, transfer-property=PENDING
          signal isigCMP_CommunicationTimeOut: start 13, 1 bit, little-endian, system signal syssigCMP_CommunicationTimeOut, init-value=0, base-type=uint8, compu-method=CMP_CommunicationTimeOut, transfer-property=PENDING
          signal isigCMP_DrivePowerSupplyError: start 11, 1 bit, little-endian, system signal syssigCMP_DrivePowerSupplyError, init-value=0, base-type=uint8, compu-method=CMP_DrivePowerSupplyError, transfer-property=PENDING
          signal isigCMP_DriveHallError: start 9, 1 bit, little-endian, system signal syssigCMP_DriveHallError, init-value=0, base-type=uint8, compu-method=CMP_DriveHallError, transfer-property=PENDING
          signal isigCMP_DriveEEPROMError: start 10, 1 bit, little-endian, system signal syssigCMP_DriveEEPROMError, init-value=0, base-type=uint8, compu-method=CMP_DriveEEPROMError, transfer-property=PENDING
          signal isigCMP_MotorOverTemp: start 4, 1 bit, little-endian, system signal syssigCMP_MotorOverTemp, init-value=0, base-type=uint8, compu-method=CMP_MotorOverTemp, transfer-property=PENDING
          signal isigCMP_DriveOverTemp: start 5, 1 bit, little-endian, system signal syssigCMP_DriveOverTemp, init-value=0, base-type=uint8, compu-method=CMP_DriveOverTemp, transfer-property=PENDING
          signal isigCMP_EEPROM: start 3, 1 bit, little-endian, system signal syssigCMP_EEPROM, init-value=0, base-type=uint8, compu-method=CMP_EEPROM, transfer-property=PENDING
          signal isigCMP_HVIL: start 2, 1 bit, little-endian, system signal syssigCMP_HVIL, init-value=0, base-type=uint8, compu-method=CMP_HVIL, transfer-property=PENDING
          signal isigCMP_DriveOverVoltage: start 7, 1 bit, little-endian, system signal syssigCMP_DriveOverVoltage, init-value=0, base-type=uint8, compu-method=CMP_DriveOverVoltage, transfer-property=PENDING
          signal isigCMP_DriveLowVoltage: start 8, 1 bit, little-endian, system signal syssigCMP_DriveLowVoltage, init-value=0, base-type=uint8, compu-method=CMP_DriveLowVoltage, transfer-property=PENDING
          signal isigCMP_DriveOverCurrent: start 6, 1 bit, little-endian, system signal syssigCMP_DriveOverCurrent, init-value=0, base-type=uint8, compu-method=CMP_DriveOverCurrent, transfer-property=PENDING
          signal isigCMP_Ready: start 1, 1 bit, little-endian, system signal syssigCMP_Ready, init-value=0, base-type=uint8, compu-method=CMP_Ready, transfer-property=PENDING
      frame frameCVM4_RESP: id 0x18FF6410, from CVM4, to FCU, frame-length=8, can-addressing-mode=EXTENDED
        pdu ipduCVM4_RESP: length=8
          signal isigCVM4_VMin: start 16, 8 bit, little-endian, system signal syssigCVM4_VMin, init-value=0, base-type=uint8, compu-method=CVM4_VMin, transfer-property=PENDING, to FCU
          signal isigCVM4_Total: start 32, 16 bit, little-endian, system signal syssigCVM4_Total, init-value=0, base-type=uint16, compu-method=CVM4_Total, transfer-property=PENDING, to FCU
          signal isigCVM4_Var: start 48, 16 bit, little-endian, system signal syssigCVM4_Var, init-value=0, base-type=uint16, compu-method=CVM4_Var, transfer-property=PENDING, to FCU
          signal isigCVM4_VMaxCH: start 8, 8 bit, little-endian, system signal syssigCVM4_VMaxCH, init-value=0, base-type=uint8, compu-method=CVM4_VMaxCH, transfer-property=PENDING, to FCU
          signal isigCVM4_VMax: start 0, 8 bit, little-endian, system signal syssigCVM4_VMax, init-value=0, base-type=uint8, compu-method=CVM4_VMax, transfer-property=PENDING, to FCU
          signal isigCVM4_VMinCH: start 24, 8 bit, little-endian, system signal syssigCVM4_VMinCH, init-value=0, base-type=uint8, compu-method=CVM4_VMinCH, transfer-property=PENDING, to FCU
      frame frameCVM1_TriggeredRESP2: id 0x18FF61B0, from CVM1, to FCU, frame-length=8, can-addressing-mode=EXTENDED
        pdu ipduCVM1_TriggeredRESP2: length=8
          signal isigCVM1_V11: start 16, 8 bit, little-endian, system signal syssigCVM1_V11, init-value=0, base-type=uint8, compu-method=CVM1_V11, transfer-property=PENDING, to FCU
          signal isigCVM1_V09: start 0, 8 bit, little-endian, system signal syssigCVM1_V09, init-value=0, base-type=uint8, compu-method=CVM1_V09, transfer-property=PENDING, to FCU
          signal isigCVM1_V12: start 24, 8 bit, little-endian, system signal syssigCVM1_V12, init-value=0, base-type=uint8, compu-method=CVM1_V12, transfer-property=PENDING, to FCU
          signal isigCVM1_V14: start 40, 8 bit, little-endian, system signal syssigCVM1_V14, init-value=0, base-type=uint8, compu-method=CVM1_V14, transfer-property=PENDING, to FCU
          signal isigCVM1_V16: start 56, 8 bit, little-endian, system signal syssigCVM1_V16, init-value=0, base-type=uint8, compu-method=CVM1_V16, transfer-property=PENDING, to FCU
          signal isigCVM1_V13: start 32, 8 bit, little-endian, system signal syssigCVM1_V13, init-value=0, base-type=uint8, compu-method=CVM1_V13, transfer-property=PENDING, to FCU
          signal isigCVM1_V10: start 8, 8 bit, little-endian, system signal syssigCVM1_V10, init-value=0, base-type=uint8, compu-method=CVM1_V10, transfer-property=PENDING, to FCU
          signal isigCVM1_V15: start 48, 8 bit, little-endian, system signal syssigCVM1_V15, init-value=0, base-type=uint8, compu-method=CVM1_V15, transfer-property=PENDING, to FCU
      frame frameCVM1_TriggeredRESP1: id 0x18FF61A0, from CVM1, to FCU, frame-length=8, can-addressing-mode=EXTENDED
        pdu ipduCVM1_TriggeredRESP1: length=8
          signal isigCVM1_V07: start 48, 8 bit, little-endian, system signal syssigCVM1_V07, init-value=0, base-type=uint8, compu-method=CVM1_V07, transfer-property=PENDING, to FCU
          signal isigCVM1_V04: start 24, 8 bit, little-endian, system signal syssigCVM1_V04, init-value=0, base-type=uint8, compu-method=CVM1_V04, transfer-property=PENDING, to FCU
          signal isigCVM1_V01: start 0, 8 bit, little-endian, system signal syssigCVM1_V01, init-value=0, base-type=uint8, compu-method=CVM1_V01, transfer-property=PENDING, to FCU
          signal isigCVM1_V03: start 16, 8 bit, little-endian, system signal syssigCVM1_V03, init-value=0, base-type=uint8, compu-method=CVM1_V03, transfer-property=PENDING, to FCU
          signal isigCVM1_V05: start 32, 8 bit, little-endian, system signal syssigCVM1_V05, init-value=0, base-type=uint8, compu-method=CVM1_V05, transfer-property=PENDING, to FCU
          signal isigCVM1_V02: start 8, 8 bit, little-endian, system signal syssigCVM1_V02, init-value=0, base-type=uint8, compu-method=CVM1_V02, transfer-property=PENDING, to FCU
          signal isigCVM1_V08: start 56, 8 bit, little-endian, system signal syssigCVM1_V08, init-value=0, base-type=uint8, compu-method=CVM1_V08, transfer-property=PENDING, to FCU
          signal isigCVM1_V06: start 40, 8 bit, little-endian, system signal syssigCVM1_V06, init-value=0, base-type=uint8, compu-method=CVM1_V06, transfer-property=PENDING, to FCU
      frame frameCVM1_TriggeredRESP3: id 0x18FF61C0, from CVM1, to FCU, frame-length=8, can-addressing-mode=EXTENDED
        pdu ipduCVM1_TriggeredRESP3: length=8
          signal isigCVM1_V22: start 40, 8 bit, little-endian, system signal syssigCVM1_V22, init-value=0, base-type=uint8, compu-method=CVM1_V22, transfer-property=PENDING, to FCU
          signal isigCVM1_V21: start 32, 8 bit, little-endian, system signal syssigCVM1_V21, init-value=0, base-type=uint8, compu-method=CVM1_V21, transfer-property=PENDING, to FCU
          signal isigCVM1_V23: start 48, 8 bit, little-endian, system signal syssigCVM1_V23, init-value=0, base-type=uint8, compu-method=CVM1_V23, transfer-property=PENDING, to FCU
          signal isigCVM1_V18: start 8, 8 bit, little-endian, system signal syssigCVM1_V18, init-value=0, base-type=uint8, compu-method=CVM1_V18, transfer-property=PENDING, to FCU
          signal isigCVM1_V19: start 16, 8 bit, little-endian, system signal syssigCVM1_V19, init-value=0, base-type=uint8, compu-method=CVM1_V19, transfer-property=PENDING, to FCU
          signal isigCVM1_V17: start 0, 8 bit, little-endian, system signal syssigCVM1_V17, init-value=0, base-type=uint8, compu-method=CVM1_V17, transfer-property=PENDING, to FCU
          signal isigCVM1_V20: start 24, 8 bit, little-endian, system signal syssigCVM1_V20, init-value=0, base-type=uint8, compu-method=CVM1_V20, transfer-property=PENDING, to FCU
          signal isigCVM1_V24: start 56, 8 bit, little-endian, system signal syssigCVM1_V24, init-value=0, base-type=uint8, compu-method=CVM1_V24, transfer-property=PENDING, to FCU
      frame frameCVM2_RESP: id 0x18FF6210, from CVM2, to FCU, frame-length=8, can-addressing-mode=EXTENDED
        pdu ipduCVM2_RESP: length=8
          signal isigCVM2_Var: start 48, 16 bit, little-endian, system signal syssigCVM2_Var, init-value=0, base-type=uint16, compu-method=CVM2_Var, transfer-property=PENDING, to FCU
          signal isigCVM2_VMax: start 0, 8 bit, little-endian, system signal syssigCVM2_VMax, init-value=0, base-type=uint8, compu-method=CVM2_VMax, transfer-property=PENDING, to FCU
          signal isigCVM2_VMinCH: start 24, 8 bit, little-endian, system signal syssigCVM2_VMinCH, init-value=0, base-type=uint8, compu-method=CVM2_VMinCH, transfer-property=PENDING, to FCU
          signal isigCVM2_Total: start 32, 16 bit, little-endian, system signal syssigCVM2_Total, init-value=0, base-type=uint16, compu-method=CVM2_Total, transfer-property=PENDING, to FCU
          signal isigCVM2_VMin: start 16, 8 bit, little-endian, system signal syssigCVM2_VMin, init-value=0, base-type=uint8, compu-method=CVM2_VMin, transfer-property=PENDING, to FCU
          signal isigCVM2_VMaxCH: start 8, 8 bit, little-endian, system signal syssigCVM2_VMaxCH, init-value=0, base-type=uint8, compu-method=CVM2_VMaxCH, transfer-property=PENDING, to FCU
      frame frameCVM2_TriggeredRESP3: id 0x18FF62C0, from CVM2, to FCU, frame-length=8, can-addressing-mode=EXTENDED
        pdu ipduCVM2_TriggeredRESP3: length=8
          signal isigCVM2_V17: start 0, 8 bit, little-endian, system signal syssigCVM2_V17, init-value=0, base-type=uint8, compu-method=CVM2_V17, transfer-property=PENDING, to FCU
          signal isigCVM2_V19: start 16, 8 bit, little-endian, system signal syssigCVM2_V19, init-value=0, base-type=uint8, compu-method=CVM2_V19, transfer-property=PENDING, to FCU
          signal isigCVM2_V20: start 24, 8 bit, little-endian, system signal syssigCVM2_V20, init-value=0, base-type=uint8, compu-method=CVM2_V20, transfer-property=PENDING, to FCU
          signal isigCVM2_V22: start 40, 8 bit, little-endian, system signal syssigCVM2_V22, init-value=0, base-type=uint8, compu-method=CVM2_V22, transfer-property=PENDING, to FCU
          signal isigCVM2_V24: start 56, 8 bit, little-endian, system signal syssigCVM2_V24, init-value=0, base-type=uint8, compu-method=CVM2_V24, transfer-property=PENDING, to FCU
          signal isigCVM2_V18: start 8, 8 bit, little-endian, system signal syssigCVM2_V18, init-value=0, base-type=uint8, compu-method=CVM2_V18, transfer-property=PENDING, to FCU
          signal isigCVM2_V23: start 48, 8 bit, little-endian, system signal syssigCVM2_V23, init-value=0, base-type=uint8, compu-method=CVM2_V23, transfer-property=PENDING, to FCU
          signal isigCVM2_V21: start 32, 8 bit, little-endian, system signal syssigCVM2_V21, init-value=0, base-type=uint8, compu-method=CVM2_V21, transfer-property=PENDING, to FCU
      frame frameCVM2_TriggeredRESP2: id 0x18FF62B0, from CVM2, to FCU, frame-length=8, can-addressing-mode=EXTENDED
        pdu ipduCVM2_TriggeredRESP2: length=8
          signal isigCVM2_V13: start 32, 8 bit, little-endian, system signal syssigCVM2_V13, init-value=0, base-type=uint8, compu-method=CVM2_V13, transfer-property=PENDING, to FCU
          signal isigCVM2_V11: start 16, 8 bit, little-endian, system signal syssigCVM2_V11, init-value=0, base-type=uint8, compu-method=CVM2_V11, transfer-property=PENDING, to FCU
          signal isigCVM2_V15: start 48, 8 bit, little-endian, system signal syssigCVM2_V15, init-value=0, base-type=uint8, compu-method=CVM2_V15, transfer-property=PENDING, to FCU
          signal isigCVM2_V16: start 56, 8 bit, little-endian, system signal syssigCVM2_V16, init-value=0, base-type=uint8, compu-method=CVM2_V16, transfer-property=PENDING, to FCU
          signal isigCVM2_V09: start 0, 8 bit, little-endian, system signal syssigCVM2_V09, init-value=0, base-type=uint8, compu-method=CVM2_V09, transfer-property=PENDING, to FCU
          signal isigCVM2_V10: start 8, 8 bit, little-endian, system signal syssigCVM2_V10, init-value=0, base-type=uint8, compu-method=CVM2_V10, transfer-property=PENDING, to FCU
          signal isigCVM2_V12: start 24, 8 bit, little-endian, system signal syssigCVM2_V12, init-value=0, base-type=uint8, compu-method=CVM2_V12, transfer-property=PENDING, to FCU
          signal isigCVM2_V14: start 40, 8 bit, little-endian, system signal syssigCVM2_V14, init-value=0, base-type=uint8, compu-method=CVM2_V14, transfer-property=PENDING, to FCU
      frame frameCVM2_TriggeredRESP1: id 0x18FF62A0, from CVM2, to FCU, frame-length=8, can-addressing-mode=EXTENDED
        pdu ipduCVM2_TriggeredRESP1: length=8
          signal isigCVM2_V03: start 16, 8 bit, little-endian, system signal syssigCVM2_V03, init-value=0, base-type=uint8, compu-method=CVM2_V03, transfer-property=PENDING, to FCU
          signal isigCVM2_V06: start 40, 8 bit, little-endian, system signal syssigCVM2_V06, init-value=0, base-type=uint8, compu-method=CVM2_V06, transfer-property=PENDING, to FCU
          signal isigCVM2_V04: start 24, 8 bit, little-endian, system signal syssigCVM2_V04, init-value=0, base-type=uint8, compu-method=CVM2_V04, transfer-property=PENDING, to FCU
          signal isigCVM2_V02: start 8, 8 bit, little-endian, system signal syssigCVM2_V02, init-value=0, base-type=uint8, compu-method=CVM2_V02, transfer-property=PENDING, to FCU
          signal isigCVM2_V08: start 56, 8 bit, little-endian, system signal syssigCVM2_V08, init-value=0, base-type=uint8, compu-method=CVM2_V08, transfer-property=PENDING, to FCU
          signal isigCVM2_V07: start 48, 8 bit, little-endian, system signal syssigCVM2_V07, init-value=0, base-type=uint8, compu-method=CVM2_V07, transfer-property=PENDING, to FCU
          signal isigCVM2_V05: start 32, 8 bit, little-endian, system signal syssigCVM2_V05, init-value=0, base-type=uint8, compu-method=CVM2_V05, transfer-property=PENDING, to FCU
          signal isigCVM2_V01: start 0, 8 bit, little-endian, system signal syssigCVM2_V01, init-value=0, base-type=uint8, compu-method=CVM2_V01, transfer-property=PENDING, to FCU
      frame frameHCU_RESP1: id 0x18FF2110, from HCU, to FCU, frame-length=8, can-addressing-mode=EXTENDED
        pdu ipduHCU_RESP1: length=8, minimum-delay=0.0, transmission-mode-true-timing=cyclic-timing={time-offset=0.0, time-period=0.1}
          signal isigT_HTank2: start 8, 8 bit, little-endian, system signal syssigT_HTank2, init-value=0, base-type=uint8, compu-method=T_HTank2, transfer-property=PENDING, to FCU
          signal isigC_HC2: start 32, 8 bit, little-endian, system signal syssigC_HC2, init-value=0, base-type=uint8, compu-method=C_HC2, transfer-property=PENDING, to FCU
          signal isigC_HC1: start 24, 8 bit, little-endian, system signal syssigC_HC1, init-value=0, base-type=uint8, compu-method=C_HC1, transfer-property=PENDING, to FCU
          signal isigT_HTank1: start 0, 8 bit, little-endian, system signal syssigT_HTank1, init-value=0, base-type=uint8, compu-method=T_HTank1, transfer-property=PENDING, to FCU
          signal isigC_HC3: start 40, 8 bit, little-endian, system signal syssigC_HC3, init-value=0, base-type=uint8, compu-method=C_HC3, transfer-property=PENDING
          signal isigP_HMid: start 48, 16 bit, little-endian, system signal syssigP_HMid, init-value=0, base-type=uint16, compu-method=P_HMid, transfer-property=PENDING
          signal isigT_HTank3: start 16, 8 bit, little-endian, system signal syssigT_HTank3, init-value=0, base-type=uint8, compu-method=T_HTank3, transfer-property=PENDING, to FCU
      frame frameCANC_HCU_CMD_Manual: id 0xFF2101, from FCU, to HCU, frame-length=8, can-addressing-mode=EXTENDED
        pdu ipduCANC_HCU_CMD_Manual: length=8, minimum-delay=0.0, transmission-mode-true-timing=cyclic-timing={time-offset=0.0, time-period=0.1}
          signal isigHCU_Mode_Manual: start 56, 8 bit, little-endian, system signal syssigHCU_Mode_Manual, init-value=0, base-type=uint8, compu-method=HCU_Mode_Manual, transfer-property=PENDING, to HCU
          signal isigHTank3_SOV_Manual: start 42, 1 bit, little-endian, system signal syssigHTank3_SOV_Manual, init-value=0, base-type=uint8, compu-method=HTank3_SOV_Manual, transfer-property=PENDING, to HCU
          signal isigHMid_SOV_Manual: start 55, 1 bit, little-endian, system signal syssigHMid_SOV_Manual, init-value=0, base-type=uint8, compu-method=HMid_SOV_Manual, transfer-property=PENDING
          signal isigHTank1_SOV_Manual: start 40, 1 bit, little-endian, system signal syssigHTank1_SOV_Manual, init-value=0, base-type=uint8, compu-method=HTank1_SOV_Manual, transfer-property=PENDING, to HCU
          signal isigHTank2_SOV_Manual: start 41, 1 bit, little-endian, system signal syssigHTank2_SOV_Manual, init-value=0, base-type=uint8, compu-method=HTank2_SOV_Manual, transfer-property=PENDING, to HCU
      frame frameHCU_RESP2: id 0x18FF2120, from HCU, to FCU, frame-length=8, can-addressing-mode=EXTENDED
        pdu ipduHCU_RESP2: length=8
          signal isigHCU_StateMachine: start 56, 4 bit, little-endian, system signal syssigHCU_StateMachine, init-value=0, base-type=uint8, compu-method=HCU_StateMachine, transfer-property=PENDING, to FCU
          signal isigHCU_ErrGrade: start 60, 4 bit, little-endian, system signal syssigHCU_ErrGrade, init-value=0, base-type=uint8, compu-method=HCU_ErrGrade, transfer-property=PENDING, to FCU
          signal isigP_HTank: start 0, 16 bit, little-endian, system signal syssigP_HTank, init-value=0, base-type=uint16, compu-method=P_HTank, transfer-property=PENDING, to FCU
          signal isigHCU_ErrCode: start 40, 16 bit, little-endian, system signal syssigHCU_ErrCode, init-value=0, base-type=uint16, compu-method=HCU_ErrCode, transfer-property=PENDING, to FCU
          signal isigSOC_H: start 16, 16 bit, little-endian, system signal syssigSOC_H, init-value=0, base-type=uint16, compu-method=SOC_H, transfer-property=PENDING
package /Communication/Pdu
  pdu ipduVECTOR__INDEPENDENT_SIG_MSG: length=0
    signal isigFCU_DevCtl: start 0, 16 bit, little-endian, system signal syssigFCU_DevCtl, init-value=0, base-type=uint16, compu-method=FCU_DevCtl, transfer-property=PENDING
    signal isigFCU_DevFB: start 0, 16 bit, little-endian, system signal syssigFCU_DevFB, init-value=0, base-type=uint16, compu-method=FCU_DevFB, transfer-property=PENDING
  pdu ipduCANC_FCU_Debug_CMD1: length=8
    signal isigQ_ASet: start 0, 16 bit, little-endian, system signal syssigQ_ASet, init-value=0, base-type=uint16, compu-method=Q_ASet, transfer-property=PENDING
    signal isigP_AInSet: start 16, 16 bit, little-endian, system signal syssigP_AInSet, init-value=0, base-type=uint16, compu-method=P_AInSet, transfer-property=PENDING
  pdu ipduCANC_FCU_Debug_CMD2: length=8
    signal isigTime_HInPurge: start 32, 16 bit, little-endian, system signal syssigTime_HInPurge, init-value=0, base-type=uint16, compu-method=Time_HInPurge, transfer-property=PENDING
    signal isigTime_HPurge: start 0, 16 bit, little-endian, system signal syssigTime_HPurge, init-value=0, base-type=uint16, compu-method=Time_HPurge, transfer-property=PENDING
    signal isigTimeOn_HPurge: start 16, 16 bit, little-endian, system signal syssigTimeOn_HPurge, init-value=0, base-type=uint16, compu-method=TimeOn_HPurge, transfer-property=PENDING
    signal isigTimeOn_HInPurge: start 48, 16 bit, little-endian, system signal syssigTimeOn_HInPurge, init-value=0, base-type=uint16, compu-method=TimeOn_HInPurge, transfer-property=PENDING
  pdu ipduFCU_H_RESP1: length=8
    signal isigP_HOut: start 32, 16 bit, little-endian, system signal syssigP_HOut, init-value=0, base-type=uint16, compu-method=P_HOut, transfer-property=PENDING
    signal isigP_HIn: start 16, 16 bit, little-endian, system signal syssigP_HIn, init-value=0, base-type=uint16, compu-method=P_HIn, transfer-property=PENDING
    signal isigP_HM: start 0, 16 bit, little-endian, system signal syssigP_HM, init-value=0, base-type=uint16, compu-method=P_HM, transfer-property=PENDING
    signal isigT_HIn: start 48, 8 bit, little-endian, system signal syssigT_HIn, init-value=0, base-type=uint8, compu-method=T_HIn, transfer-property=PENDING
  pdu ipduFCU_H_RESP2: length=8
    signal isigC_HEZ: start 8, 8 bit, little-endian, system signal syssigC_HEZ, init-value=0, base-type=uint8, compu-method=C_HEZ, transfer-property=PENDING
    signal isigC_HPZ: start 16, 8 bit, little-endian, system signal syssigC_HPZ, init-value=0, base-type=uint8, compu-method=C_HPZ, transfer-property=PENDING
    signal isigC_HAE: start 0, 8 bit, little-endian, system signal syssigC_HAE, init-value=0, base-type=uint8, compu-method=C_HAE, transfer-property=PENDING
  pdu ipduFCU_RESP2: length=8
    signal isigFCU_ErrCode: start 24, 16 bit, little-endian, system signal syssigFCU_ErrCode, init-value=0, base-type=uint16, compu-method=FCU_ErrCode, transfer-property=PENDING
    signal isigFCU_ExtendedState: start 56, 4 bit, little-endian, system signal syssigFCU_ExtendedState, init-value=0, base-type=uint8, compu-method=FCU_ExtendedState, transfer-property=PENDING
    signal isigFCU_BaseState: start 60, 4 bit, little-endian, system signal syssigFCU_BaseState, init-value=0, base-type=uint8, compu-method=FCU_BaseState, transfer-property=PENDING
    signal isigFCU_ErrGrade: start 40, 8 bit, little-endian, system signal syssigFCU_ErrGrade, init-value=0, base-type=uint8, compu-method=FCU_ErrGrade, transfer-property=PENDING
    signal isigFCU_StepCtl: start 0, 16 bit, little-endian, system signal syssigFCU_StepCtl, init-value=0, base-type=uint16, compu-method=FCU_StepCtl, transfer-property=PENDING
  pdu ipduFCU_RESP1: length=8
    signal isigSOV_HInPurge_FB: start 2, 1 bit, little-endian, system signal syssigSOV_HInPurge_FB, init-value=0, base-type=uint8, compu-method=SOV_HInPurge_FB, transfer-property=PENDING
    signal isigCNT_Baterry_FB: start 11, 1 bit, little-endian, system signal syssigCNT_Baterry_FB, init-value=0, base-type=uint8, compu-method=CNT_Baterry_FB, transfer-property=PENDING
    signal isigCNT_HCUValve_FB: start 6, 1 bit, little-endian, system signal syssigCNT_HCUValve_FB, init-value=0, base-type=uint8, compu-method=CNT_HCUValve_FB, transfer-property=PENDING
    signal isigCNT_FC_FB: start 0, 1 bit, little-endian, system signal syssigCNT_FC_FB, init-value=0, base-type=uint8, compu-method=CNT_FC_FB, transfer-property=PENDING
    signal isigCNT_CMPLowVoltage_FB: start 7, 1 bit, little-endian, system signal syssigCNT_CMPLowVoltage_FB, init-value=0, base-type=uint8, compu-method=CNT_CMPLowVoltage_FB, transfer-property=PENDING
    signal isigFCS_GenEnergy: start 32, 32 bit, little-endian, system signal syssigFCS_GenEnergy, init-value=0, base-type=uint32, compu-method=FCS_GenEnergy, transfer-property=PENDING
    signal isigCNT_HRB_FB: start 8, 1 bit, little-endian, system signal syssigCNT_HRB_FB, init-value=0, base-type=uint8, compu-method=CNT_HRB_FB, transfer-property=PENDING
    signal isigCNT_DCFOutputPreCharge_FB: start 10, 1 bit, little-endian, system signal syssigCNT_DCFOutputPreCharge_FB, init-value=0, base-type=uint8, compu-method=CNT_DCFOutputPreCharge_FB, transfer-property=PENDING
    signal isigCNT_DCFOutput_FB: start 9, 1 bit, little-endian, system signal syssigCNT_DCFOutput_FB, init-value=0, base-type=uint8, compu-method=CNT_DCFOutput_FB, transfer-property=PENDING
    signal isigCNT_HCU_FB: start 5, 1 bit, little-endian, system signal syssigCNT_HCU_FB, init-value=0, base-type=uint8, compu-method=CNT_HCU_FB, transfer-property=PENDING
    signal isigSOV_HPurge_FB: start 1, 1 bit, little-endian, system signal syssigSOV_HPurge_FB, init-value=0, base-type=uint8, compu-method=SOV_HPurge_FB, transfer-property=PENDING
    signal isigSOV_HM_FB: start 3, 1 bit, little-endian, system signal syssigSOV_HM_FB, init-value=0, base-type=uint8, compu-method=SOV_HM_FB, transfer-property=PENDING
    signal isigSOV_AHB_FB: start 4, 1 bit, little-endian, system signal syssigSOV_AHB_FB, init-value=0, base-type=uint8, compu-method=SOV_AHB_FB, transfer-property=PENDING
  pdu ipduFCU_A_RESP3: length=8
    signal isigPos_BPCV: start 56, 8 bit, little-endian, system signal syssigPos_BPCV, init-value=0, base-type=uint8, compu-method=Pos_BPCV, transfer-property=PENDING
    signal isigQ_A: start 0, 16 bit, little-endian, system signal syssigQ_A, init-value=0, base-type=uint16, compu-method=Q_A, transfer-property=PENDING
  pdu ipduFCU_A_RESP2: length=8
    signal isigT_AIn: start 32, 8 bit, little-endian, system signal syssigT_AIn, init-value=0, base-type=uint8, compu-method=T_AIn, transfer-property=PENDING
    signal isigT_AOut: start 40, 8 bit, little-endian, system signal syssigT_AOut, init-value=0, base-type=uint8, compu-method=T_AOut, transfer-property=PENDING
    signal isigT_AMB: start 16, 8 bit, little-endian, system signal syssigT_AMB, init-value=0, base-type=uint8, compu-method=T_AMB, transfer-property=PENDING
  pdu ipduFCU_A_RESP1: length=8
    signal isigP_AOut: start 48, 16 bit, little-endian, system signal syssigP_AOut, init-value=0, base-type=uint16, compu-method=P_AOut, transfer-property=PENDING
    signal isigP_AMB: start 0, 16 bit, little-endian, system signal syssigP_AMB, init-value=0, base-type=uint16, compu-method=P_AMB, transfer-property=PENDING
    signal isigP_AIn: start 32, 16 bit, little-endian, system signal syssigP_AIn, init-value=0, base-type=uint16, compu-method=P_AIn, transfer-property=PENDING
  pdu ipduCANC_FCU_CMD: length=8
    signal isigCNT_HCUValve_CMD: start 46, 1 bit, little-endian, system signal syssigCNT_HCUValve_CMD, init-value=0, base-type=uint8, compu-method=CNT_HCUValve_CMD, transfer-property=PENDING
    signal isigCNT_DCFOutput_CMD: start 49, 1 bit, little-endian, system signal syssigCNT_DCFOutput_CMD, init-value=0, base-type=uint8, compu-method=CNT_DCFOutput_CMD, transfer-property=PENDING
    signal isigP_PCVSet: start 0, 16 bit, little-endian, system signal syssigP_PCVSet, init-value=0, base-type=uint16, compu-method=P_PCVSet, transfer-property=PENDING
    signal isigCNT_HRB_CMD: start 48, 1 bit, little-endian, system signal syssigCNT_HRB_CMD, init-value=0, base-type=uint8, compu-method=CNT_HRB_CMD, transfer-property=PENDING
    signal isigSOV_HM_CMD: start 43, 1 bit, little-endian, system signal syssigSOV_HM_CMD, init-value=0, base-type=uint8, compu-method=SOV_HM_CMD, transfer-property=PENDING
    signal isigFCU_Mode: start 56, 8 bit, little-endian, system signal syssigFCU_Mode, init-value=0, base-type=uint8, compu-method=FCU_Mode, transfer-property=PENDING
    signal isigCNT_FC_CMD: start 40, 1 bit, little-endian, system signal syssigCNT_FC_CMD, init-value=0, base-type=uint8, compu-method=CNT_FC_CMD, transfer-property=PENDING
    signal isigSOV_AHB_CMD: start 44, 1 bit, little-endian, system signal syssigSOV_AHB_CMD, init-value=0, base-type=uint8, compu-method=SOV_AHB_CMD, transfer-property=PENDING
    signal isigSOV_HInPurge_CMD: start 42, 1 bit, little-endian, system signal syssigSOV_HInPurge_CMD, init-value=0, base-type=uint8, compu-method=SOV_HInPurge_CMD, transfer-property=PENDING
    signal isigCNT_Baterry_CMD: start 51, 1 bit, little-endian, system signal syssigCNT_Baterry_CMD, init-value=0, base-type=uint8, compu-method=CNT_Baterry_CMD, transfer-property=PENDING
    signal isigCNT_HCU_CMD: start 45, 1 bit, little-endian, system signal syssigCNT_HCU_CMD, init-value=0, base-type=uint8, compu-method=CNT_HCU_CMD, transfer-property=PENDING
    signal isigSOV_HPurge_CMD: start 41, 1 bit, little-endian, system signal syssigSOV_HPurge_CMD, init-value=0, base-type=uint8, compu-method=SOV_HPurge_CMD, transfer-property=PENDING
    signal isigCNT_DCFOutputPreCharge_CMD: start 50, 1 bit, little-endian, system signal syssigCNT_DCFOutputPreCharge_CMD, init-value=0, base-type=uint8, compu-method=CNT_DCFOutputPreCharge_CMD, transfer-property=PENDING
    signal isigCNT_CMPLowVoltage_CMD: start 47, 1 bit, little-endian, system signal syssigCNT_CMPLowVoltage_CMD, init-value=0, base-type=uint8, compu-method=CNT_CMPLowVoltage_CMD, transfer-property=PENDING
    signal isigPos_BPCVSet: start 24, 8 bit, little-endian, system signal syssigPos_BPCVSet, init-value=0, base-type=uint8, compu-method=Pos_BPCVSet, transfer-property=PENDING
package /Communication/ISignalPduGroup
  24 x i signal i pdu group:
    ipdugroupCVM10OUT: communication-direction=OUT, i-signal-i-pdus=[ipduCVM10_TriggeredRESP3, ipduCVM10_TriggeredRESP1, ipduCVM10_TriggeredRESP2, ipduCVM10_RESP]
    ipdugroupFCUIN: communication-direction=IN
      i-signal-i-pdus:
        ipduCVM10_TriggeredRESP3
        ipduCVM4_TriggeredRESP1
        ipduCVM12_RESP
        ipduCVM10_TriggeredRESP1
        ipduCVM9_TriggeredRESP1
        ipduCVM10_TriggeredRESP2
        ipduCVM9_TriggeredRESP2
        ipduCVM9_TriggeredRESP3
        ipduCVM8_RESP
        ipduCVM1_RESP
        ipduCVM11_RESP
        ipduDCF_RESP1
        ipduDCF_RESP2
        ipduCVM7_RESP
        ipduCVM4_TriggeredRESP3
        ipduCVM4_TriggeredRESP2
        ipduCVM3_RESP
        ipduCVM9_RESP
        ipduHRB_RESP
        ipduCVM12_TriggeredRESP3
        ipduCVM6_RESP
        ipduCVM7_TriggeredRESP{1..3}
        ipduCVM12_TriggeredRESP1
        ipduCVM12_TriggeredRESP2
        ipduCVM6_TriggeredRESP2
        ipduCVM10_RESP
        ipduCVM6_TriggeredRESP3
        ipduCVM6_TriggeredRESP1
        ipduCVM11_TriggeredRESP1
        ipduCVM5_RESP
        ipduCVM3_TriggeredRESP2
        ipduCVM3_TriggeredRESP1
        ipduCVM5_TriggeredRESP1
        ipduCVM5_TriggeredRESP2
        ipduCVM3_TriggeredRESP3
        ipduCANC_DCF_CMD_Manual
        ipduCVM5_TriggeredRESP3
        ipduCVM11_TriggeredRESP2
        ipduCVM11_TriggeredRESP3
        ipduDCU_RESP1
        ipduDCU_RESP2
        ipduCVM8_TriggeredRESP2
        ipduCVM8_TriggeredRESP3
        ipduCVM8_TriggeredRESP1
        ipduCMP_RESP1
        ipduCVM4_RESP
        ipduCVM1_TriggeredRESP2
        ipduCVM1_TriggeredRESP1
        ipduCVM1_TriggeredRESP3
        ipduCVM2_RESP
        ipduCVM2_TriggeredRESP3
        ipduCVM2_TriggeredRESP2
        ipduCVM2_TriggeredRESP1
        ipduHCU_RESP1
        ipduHCU_RESP2
    ipdugroupCVM4OUT: communication-direction=OUT, i-signal-i-pdus=[ipduCVM4_TriggeredRESP1, ipduCVM4_TriggeredRESP3, ipduCVM4_TriggeredRESP2, ipduCVM4_RESP]
    ipdugroupFCUOUT: communication-direction=OUT
      i-signal-i-pdus:
        ipduCANC_HRB_CMD_Manual
        ipduCANC_CVM_TriggeredCMD_Manual
        ipduCANC_DCU_CMD1_Manual
        ipduCANC_DCU_CMD2_Manual
        ipduCANC_CVM_CMD_Manual
        ipduCANC_CMP_CMD_Manual
        ipduCANC_DCF_CMD_Manual
        ipduCANC_HCU_CMD_Manual
    ipdugroupHRBIN: communication-direction=IN, i-signal-i-pdus=ipduCANC_HRB_CMD_Manual
    ipdugroupCVM12OUT: communication-direction=OUT, i-signal-i-pdus=[ipduCVM12_RESP, ipduCVM12_TriggeredRESP3, ipduCVM12_TriggeredRESP1, ipduCVM12_TriggeredRESP2]
    ipdugroupCVM9OUT: communication-direction=OUT, i-signal-i-pdus=[ipduCVM9_TriggeredRESP1, ipduCVM9_TriggeredRESP2, ipduCVM9_TriggeredRESP3, ipduCVM9_RESP]
    ipdugroupCVM8OUT: communication-direction=OUT, i-signal-i-pdus=[ipduCVM8_RESP, ipduCVM8_TriggeredRESP2, ipduCVM8_TriggeredRESP3, ipduCVM8_TriggeredRESP1]
    ipdugroupCVM1OUT: communication-direction=OUT, i-signal-i-pdus=[ipduCVM1_RESP, ipduCVM1_TriggeredRESP2, ipduCVM1_TriggeredRESP1, ipduCVM1_TriggeredRESP3]
    ipdugroupCVM11OUT: communication-direction=OUT, i-signal-i-pdus=[ipduCVM11_RESP, ipduCVM11_TriggeredRESP1, ipduCVM11_TriggeredRESP2, ipduCVM11_TriggeredRESP3]
    ipdugroupDCUIN: communication-direction=IN, i-signal-i-pdus=[ipduCANC_DCU_CMD1_Manual, ipduCANC_DCU_CMD2_Manual]
    ipdugroupDCFOUT: communication-direction=OUT, i-signal-i-pdus=[ipduDCF_RESP1, ipduDCF_RESP2]
    ipdugroupCVM7OUT: communication-direction=OUT, i-signal-i-pdus=[ipduCVM7_RESP, ipduCVM7_TriggeredRESP1, ipduCVM7_TriggeredRESP2, ipduCVM7_TriggeredRESP3]
    ipdugroupCVM3OUT: communication-direction=OUT, i-signal-i-pdus=[ipduCVM3_RESP, ipduCVM3_TriggeredRESP2, ipduCVM3_TriggeredRESP1, ipduCVM3_TriggeredRESP3]
    ipdugroupHRBOUT: communication-direction=OUT, i-signal-i-pdus=ipduHRB_RESP
    ipdugroupCVM6OUT: communication-direction=OUT, i-signal-i-pdus=[ipduCVM6_RESP, ipduCVM6_TriggeredRESP2, ipduCVM6_TriggeredRESP3, ipduCVM6_TriggeredRESP1]
    ipdugroupCMPIN: communication-direction=IN, i-signal-i-pdus=ipduCANC_CMP_CMD_Manual
    ipdugroupCVM5OUT: communication-direction=OUT, i-signal-i-pdus=[ipduCVM5_RESP, ipduCVM5_TriggeredRESP1, ipduCVM5_TriggeredRESP2, ipduCVM5_TriggeredRESP3]
    ipdugroupDCFIN: communication-direction=IN, i-signal-i-pdus=ipduCANC_DCF_CMD_Manual
    ipdugroupDCUOUT: communication-direction=OUT, i-signal-i-pdus=[ipduDCU_RESP1, ipduDCU_RESP2]
    ipdugroupCMPOUT: communication-direction=OUT, i-signal-i-pdus=[ipduCMP_RESP1, ipduCMP_RESP2]
    ipdugroupCVM2OUT: communication-direction=OUT, i-signal-i-pdus=[ipduCVM2_RESP, ipduCVM2_TriggeredRESP3, ipduCVM2_TriggeredRESP2, ipduCVM2_TriggeredRESP1]
    ipdugroupHCUOUT: communication-direction=OUT, i-signal-i-pdus=[ipduHCU_RESP1, ipduHCU_RESP2]
    ipdugroupHCUIN: communication-direction=IN, i-signal-i-pdus=ipduCANC_HCU_CMD_Manual
package /Communication/Frame
  11 x can frame:
    frameVECTOR__INDEPENDENT_SIG_MSG: frame-length=0
      pdu to frame mapping mappingVECTOR__INDEPENDENT_SIG_MSG: packing-byte-order=little-endian, pdu=ipduVECTOR__INDEPENDENT_SIG_MSG, start-position=0
    frameCANC_FCU_Debug_CMD1: frame-length=8
      pdu to frame mapping mappingCANC_FCU_Debug_CMD1: packing-byte-order=little-endian, pdu=ipduCANC_FCU_Debug_CMD1, start-position=0
    frameCANC_FCU_Debug_CMD2: frame-length=8
      pdu to frame mapping mappingCANC_FCU_Debug_CMD2: packing-byte-order=little-endian, pdu=ipduCANC_FCU_Debug_CMD2, start-position=0
    frameFCU_H_RESP1: frame-length=8
      pdu to frame mapping mappingFCU_H_RESP1: packing-byte-order=little-endian, pdu=ipduFCU_H_RESP1, start-position=0
    frameFCU_H_RESP2: frame-length=8
      pdu to frame mapping mappingFCU_H_RESP2: packing-byte-order=little-endian, pdu=ipduFCU_H_RESP2, start-position=0
    frameFCU_RESP2: frame-length=8
      pdu to frame mapping mappingFCU_RESP2: packing-byte-order=little-endian, pdu=ipduFCU_RESP2, start-position=0
    frameFCU_RESP1: frame-length=8
      pdu to frame mapping mappingFCU_RESP1: packing-byte-order=little-endian, pdu=ipduFCU_RESP1, start-position=0
    frameFCU_A_RESP3: frame-length=8
      pdu to frame mapping mappingFCU_A_RESP3: packing-byte-order=little-endian, pdu=ipduFCU_A_RESP3, start-position=0
    frameFCU_A_RESP2: frame-length=8
      pdu to frame mapping mappingFCU_A_RESP2: packing-byte-order=little-endian, pdu=ipduFCU_A_RESP2, start-position=0
    frameFCU_A_RESP1: frame-length=8
      pdu to frame mapping mappingFCU_A_RESP1: packing-byte-order=little-endian, pdu=ipduFCU_A_RESP1, start-position=0
    frameCANC_FCU_CMD: frame-length=8
      pdu to frame mapping mappingCANC_FCU_CMD: packing-byte-order=little-endian, pdu=ipduCANC_FCU_CMD, start-position=0
